AUTOSAR XML (schema 4-2-2)
package /STELLANTIS/EPT/ASWCs
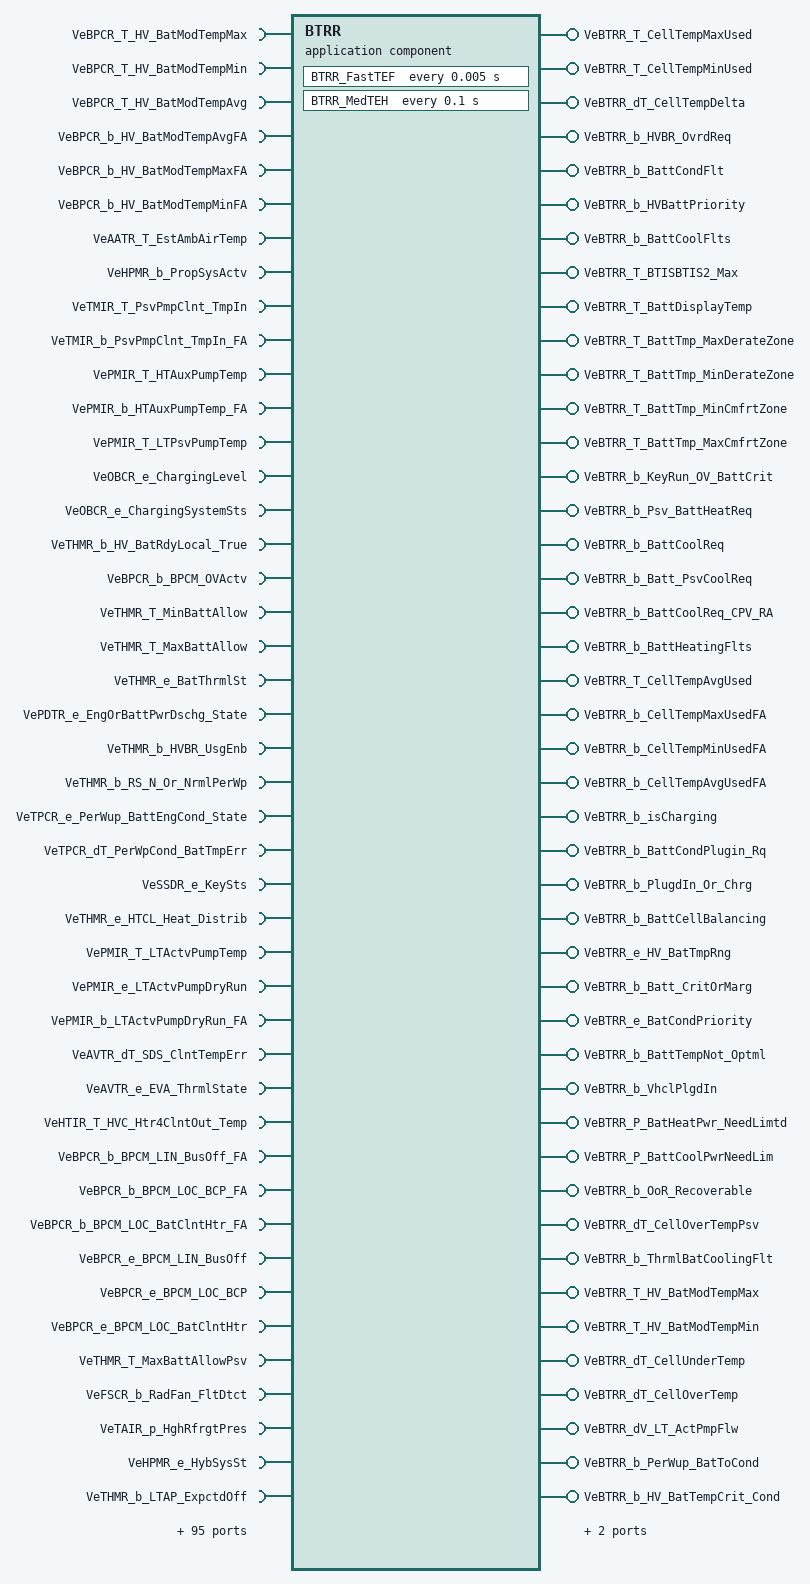
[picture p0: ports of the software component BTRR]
  application sw component type BTRR
    139 x require port:
      VeBPCR_T_HV_BatModTempMax: variation-point={short-label=vpVeBPCR_T_HV_BatModTempMax, sw-syscond=1}, nonqueued-receiver-com-spec{data-element=Value, init-value=0}, required-interface=VeBPCR_T_HV_BatModTempMax
      VeBPCR_T_HV_BatModTempMin: variation-point={short-label=vpVeBPCR_T_HV_BatModTempMin, sw-syscond=1}, nonqueued-receiver-com-spec{data-element=Value, init-value=0}, required-interface=VeBPCR_T_HV_BatModTempMin
      VeBPCR_T_HV_BatModTempAvg: variation-point={short-label=vpVeBPCR_T_HV_BatModTempAvg, sw-syscond=1}, nonqueued-receiver-com-spec{data-element=Value, init-value=0}, required-interface=VeBPCR_T_HV_BatModTempAvg
      VeBPCR_b_HV_BatModTempAvgFA: variation-point={short-label=vpVeBPCR_b_HV_BatModTempAvgFA, sw-syscond=1}, nonqueued-receiver-com-spec{data-element=Value, init-value=0}, required-interface=VeBPCR_b_HV_BatModTempAvgFA
      VeBPCR_b_HV_BatModTempMaxFA: variation-point={short-label=vpVeBPCR_b_HV_BatModTempMaxFA, sw-syscond=1}, nonqueued-receiver-com-spec{data-element=Value, init-value=0}, required-interface=VeBPCR_b_HV_BatModTempMaxFA
      VeBPCR_b_HV_BatModTempMinFA: variation-point={short-label=vpVeBPCR_b_HV_BatModTempMinFA, sw-syscond=1}, nonqueued-receiver-com-spec{data-element=Value, init-value=0}, required-interface=VeBPCR_b_HV_BatModTempMinFA
      VeAATR_T_EstAmbAirTemp: variation-point={short-label=vpVeAATR_T_EstAmbAirTemp, sw-syscond=1}, nonqueued-receiver-com-spec{data-element=Value, init-value=0}, required-interface=VeAATR_T_EstAmbAirTemp
      VeHPMR_b_PropSysActv: variation-point={short-label=vpVeHPMR_b_PropSysActv, sw-syscond=1}, nonqueued-receiver-com-spec{data-element=Value, init-value=0}, required-interface=VeHPMR_b_PropSysActv
      VeTMIR_T_PsvPmpClnt_TmpIn: variation-point={short-label=vpVeTMIR_T_PsvPmpClnt_TmpIn, sw-syscond=1}, nonqueued-receiver-com-spec{data-element=Value, init-value=0}, required-interface=VeTMIR_T_PsvPmpClnt_TmpIn
      VeTMIR_b_PsvPmpClnt_TmpIn_FA: variation-point={short-label=vpVeTMIR_b_PsvPmpClnt_TmpIn_FA, sw-syscond=1}, nonqueued-receiver-com-spec{data-element=Value, init-value=0}, required-interface=VeTMIR_b_PsvPmpClnt_TmpIn_FA
      VePMIR_T_HTAuxPumpTemp: variation-point={short-label=vpVePMIR_T_HTAuxPumpTemp, sw-syscond=1}, nonqueued-receiver-com-spec{data-element=Value, init-value=0}, required-interface=VePMIR_T_HTAuxPumpTemp
      VePMIR_b_HTAuxPumpTemp_FA: variation-point={short-label=vpVePMIR_b_HTAuxPumpTemp_FA, sw-syscond=1}, nonqueued-receiver-com-spec{data-element=Value, init-value=0}, required-interface=VePMIR_b_HTAuxPumpTemp_FA
      VePMIR_T_LTPsvPumpTemp: variation-point={short-label=vpVePMIR_T_LTPsvPumpTemp, sw-syscond=1}, nonqueued-receiver-com-spec{data-element=Value, init-value=0}, required-interface=VePMIR_T_LTPsvPumpTemp
      VeOBCR_e_ChargingLevel: variation-point={short-label=vpVeOBCR_e_ChargingLevel, sw-syscond=1}, nonqueued-receiver-com-spec{data-element=Value, init-value=CeOBCR_e_ChargingLvlDefault}, required-interface=VeOBCR_e_ChargingLevel
      VeOBCR_e_ChargingSystemSts: variation-point={short-label=vpVeOBCR_e_ChargingSystemSts, sw-syscond=1}, nonqueued-receiver-com-spec{data-element=Value, init-value=CeOBCR_e_NotCharging}, required-interface=VeOBCR_e_ChargingSystemSts
      VeTHMR_b_HV_BatRdyLocal_True: variation-point={short-label=vpVeTHMR_b_HV_BatRdyLocal_True, sw-syscond=1}, nonqueued-receiver-com-spec{data-element=Value, init-value=0}, required-interface=VeTHMR_b_HV_BatRdyLocal_True
      VeBPCR_b_BPCM_OVActv: variation-point={short-label=vpVeBPCR_b_BPCM_OVActv, sw-syscond=1}, nonqueued-receiver-com-spec{data-element=Value, init-value=0}, required-interface=VeBPCR_b_BPCM_OVActv
      VeTHMR_T_MinBattAllow: variation-point={short-label=vpVeTHMR_T_MinBattAllow, sw-syscond=1}, nonqueued-receiver-com-spec{data-element=Value, init-value=0}, required-interface=VeTHMR_T_MinBattAllow
      VeTHMR_T_MaxBattAllow: variation-point={short-label=vpVeTHMR_T_MaxBattAllow, sw-syscond=1}, nonqueued-receiver-com-spec{data-element=Value, init-value=0}, required-interface=VeTHMR_T_MaxBattAllow
      VeTHMR_e_BatThrmlSt: variation-point={short-label=vpVeTHMR_e_BatThrmlSt, sw-syscond=1}, nonqueued-receiver-com-spec{data-element=Value, init-value=CeTHMR_e_NoConditioning}, required-interface=VeTHMR_e_BatThrmlSt
      VePDTR_e_EngOrBattPwrDschg_State: variation-point={short-label=vpVePDTR_e_EngOrBattPwrDschg_State, sw-syscond=1}, nonqueued-receiver-com-spec{data-element=Value, init-value=CePDTR_e_No_Dischrg}, required-interface=VePDTR_e_EngOrBattPwrDschg_State
      VeTHMR_b_HVBR_UsgEnb: variation-point={short-label=vpVeTHMR_b_HVBR_UsgEnb, sw-syscond=1}, nonqueued-receiver-com-spec{data-element=Value, init-value=0}, required-interface=VeTHMR_b_HVBR_UsgEnb
      VeTHMR_b_RS_N_Or_NrmlPerWp: variation-point={short-label=vpVeTHMR_b_RS_N_Or_NrmlPerWp, sw-syscond=1}, nonqueued-receiver-com-spec{data-element=Value, init-value=0}, required-interface=VeTHMR_b_RS_N_Or_NrmlPerWp
      VeTPCR_e_PerWup_BattEngCond_State: variation-point={short-label=vpVeTPCR_e_PerWup_BattEngCond_State, sw-syscond=1}, nonqueued-receiver-com-spec{data-element=Value, init-value=CeTPCR_e_NoneOfEngBatt_Cond}, required-interface=VeTPCR_e_PerWup_BattEngCond_State
      VeTPCR_dT_PerWpCond_BatTmpErr: variation-point={short-label=vpVeTPCR_dT_PerWpCond_BatTmpErr, sw-syscond=1}, nonqueued-receiver-com-spec{data-element=Value, init-value=0}, required-interface=VeTPCR_dT_PerWpCond_BatTmpErr
      VeSSDR_e_KeySts: variation-point={short-label=vpVeSSDR_e_KeySts, sw-syscond=1}, nonqueued-receiver-com-spec{data-element=Value, init-value=CeSSDR_e_KeyOff}, required-interface=VeSSDR_e_KeySts
      VeTHMR_e_HTCL_Heat_Distrib: variation-point={short-label=vpVeTHMR_e_HTCL_Heat_Distrib, sw-syscond=1}, nonqueued-receiver-com-spec{data-element=Value, init-value=CeTHMR_e_NoHeating}, required-interface=VeTHMR_e_HTCL_Heat_Distrib
      VePMIR_T_LTActvPumpTemp: variation-point={short-label=vpVePMIR_T_LTActvPumpTemp, sw-syscond=1}, nonqueued-receiver-com-spec{data-element=Value, init-value=0}, required-interface=VePMIR_T_LTActvPumpTemp
      VePMIR_e_LTActvPumpDryRun: variation-point={short-label=vpVePMIR_e_LTActvPumpDryRun, sw-syscond=1}, nonqueued-receiver-com-spec{data-element=Value, init-value=CePMPR_e_FTSNA_False}, required-interface=VePMIR_e_LTActvPumpDryRun
      VePMIR_b_LTActvPumpDryRun_FA: variation-point={short-label=vpVePMIR_b_LTActvPumpDryRun_FA, sw-syscond=1}, nonqueued-receiver-com-spec{data-element=Value, init-value=0}, required-interface=VePMIR_b_LTActvPumpDryRun_FA
      VeAVTR_dT_SDS_ClntTempErr: variation-point={short-label=vpVeAVTR_dT_SDS_ClntTempErr, sw-syscond=1}, nonqueued-receiver-com-spec{data-element=Value, init-value=0}, required-interface=VeAVTR_dT_SDS_ClntTempErr
      VeAVTR_e_EVA_ThrmlState: variation-point={short-label=vpVeAVTR_e_EVA_ThrmlState, sw-syscond=1}, nonqueued-receiver-com-spec{data-element=Value, init-value=CeAVTR_e_NoEVACond}, required-interface=VeAVTR_e_EVA_ThrmlState
      VeHTIR_T_HVC_Htr4ClntOut_Temp: variation-point={short-label=vpVeHTIR_T_HVC_Htr4ClntOut_Temp, sw-syscond=1}, nonqueued-receiver-com-spec{data-element=Value, init-value=0}, required-interface=VeHTIR_T_HVC_Htr4ClntOut_Temp
      VeBPCR_b_BPCM_LIN_BusOff_FA: variation-point={short-label=vpVeBPCR_b_BPCM_LIN_BusOff_FA, sw-syscond=1}, nonqueued-receiver-com-spec{data-element=Value, init-value=0}, required-interface=VeBPCR_b_BPCM_LIN_BusOff_FA
      VeBPCR_b_BPCM_LOC_BCP_FA: variation-point={short-label=vpVeBPCR_b_BPCM_LOC_BCP_FA, sw-syscond=1}, nonqueued-receiver-com-spec{data-element=Value, init-value=0}, required-interface=VeBPCR_b_BPCM_LOC_BCP_FA
      VeBPCR_b_BPCM_LOC_BatClntHtr_FA: variation-point={short-label=vpVeBPCR_b_BPCM_LOC_BatClntHtr_FA, sw-syscond=1}, nonqueued-receiver-com-spec{data-element=Value, init-value=0}, required-interface=VeBPCR_b_BPCM_LOC_BatClntHtr_FA
      VeBPCR_e_BPCM_LIN_BusOff: variation-point={short-label=vpVeBPCR_e_BPCM_LIN_BusOff, sw-syscond=1}, nonqueued-receiver-com-spec{data-element=Value, init-value=CeBPCR_e_LIN_BusOff_Disabled}, required-interface=VeBPCR_e_BPCM_LIN_BusOff
      VeBPCR_e_BPCM_LOC_BCP: variation-point={short-label=vpVeBPCR_e_BPCM_LOC_BCP, sw-syscond=1}, nonqueued-receiver-com-spec{data-element=Value, init-value=CeBPCR_e_LOC_BCP_False}, required-interface=VeBPCR_e_BPCM_LOC_BCP
      VeBPCR_e_BPCM_LOC_BatClntHtr: variation-point={short-label=vpVeBPCR_e_BPCM_LOC_BatClntHtr, sw-syscond=1}, nonqueued-receiver-com-spec{data-element=Value, init-value=CeBPCR_e_LOC_BatClntHtr_False}, required-interface=VeBPCR_e_BPCM_LOC_BatClntHtr
      VeTHMR_T_MaxBattAllowPsv: variation-point={short-label=vpVeTHMR_T_MaxBattAllowPsv, sw-syscond=1}, nonqueued-receiver-com-spec{data-element=Value, init-value=0}, required-interface=VeTHMR_T_MaxBattAllowPsv
      VeFSCR_b_RadFan_FltDtct: variation-point={short-label=vpVeFSCR_b_RadFan_FltDtct, sw-syscond=1}, nonqueued-receiver-com-spec{data-element=Value, init-value=0}, required-interface=VeFSCR_b_RadFan_FltDtct
      VeTAIR_p_HghRfrgtPres: variation-point={short-label=vpVeTAIR_p_HghRfrgtPres, sw-syscond=1}, nonqueued-receiver-com-spec{data-element=Value, init-value=0}, required-interface=VeTAIR_p_HghRfrgtPres
      VeHPMR_e_HybSysSt: variation-point={short-label=vpVeHPMR_e_HybSysSt, sw-syscond=1}, nonqueued-receiver-com-spec{data-element=Value, init-value=CeHPMR_e_POWERUP}, required-interface=VeHPMR_e_HybSysSt
      VeTHMR_b_LTAP_ExpctdOff: variation-point={short-label=vpVeTHMR_b_LTAP_ExpctdOff, sw-syscond=1}, nonqueued-receiver-com-spec{data-element=Value, init-value=0}, required-interface=VeTHMR_b_LTAP_ExpctdOff
      VeAVTR_e_SDS_Actual_State: variation-point={short-label=vpVeAVTR_e_SDS_Actual_State, sw-syscond=1}, nonqueued-receiver-com-spec{data-element=Value, init-value=CeTRIR_e_SDS_OFF}, required-interface=VeAVTR_e_SDS_Actual_State
      VeAVTR_T_SDS_Clnt_TmpIn_Act: variation-point={short-label=vpVeAVTR_T_SDS_Clnt_TmpIn_Act, sw-syscond=1}, nonqueued-receiver-com-spec{data-element=Value, init-value=0}, required-interface=VeAVTR_T_SDS_Clnt_TmpIn_Act
      VeBPCR_e_HV_BatCntctrStat: variation-point={short-label=vpVeBPCR_e_HV_BatCntctrStat, sw-syscond=1}, nonqueued-receiver-com-spec{data-element=Value, init-value=CeHVTR_e_Open}, required-interface=VeBPCR_e_HV_BatCntctrStat
      VeIDCR_T_APMTemp1: variation-point={short-label=vpVeIDCR_T_APMTemp1, sw-syscond=1}, nonqueued-receiver-com-spec{data-element=Value, init-value=0}, required-interface=VeIDCR_T_APMTemp1
      VeIDCR_T_APMTemp2: variation-point={short-label=vpVeIDCR_T_APMTemp2, sw-syscond=1}, nonqueued-receiver-com-spec{data-element=Value, init-value=0}, required-interface=VeIDCR_T_APMTemp2
      VePMIR_e_HTAuxPumpDryRun: variation-point={short-label=vpVePMIR_e_HTAuxPumpDryRun, sw-syscond=1}, nonqueued-receiver-com-spec{data-element=Value, init-value=CePMPR_e_FTSNA_False}, required-interface=VePMIR_e_HTAuxPumpDryRun
      VePMIR_b_HTAuxPumpDryRun_FA: variation-point={short-label=vpVePMIR_b_HTAuxPumpDryRun_FA, sw-syscond=1}, nonqueued-receiver-com-spec{data-element=Value, init-value=0}, required-interface=VePMIR_b_HTAuxPumpDryRun_FA
      VeHTIR_e_HV_ElecClntHtr4_Sts: variation-point={short-label=vpVeHTIR_e_HV_ElecClntHtr4_Sts, sw-syscond=1}, nonqueued-receiver-com-spec{data-element=Value, init-value=CeHTIR_e_HtrSts_Off}, required-interface=VeHTIR_e_HV_ElecClntHtr4_Sts
      VeTRIR_T_HV_BatClntTmp_In: variation-point={short-label=vpVeTRIR_T_HV_BatClntTmp_In, sw-syscond=1}, nonqueued-receiver-com-spec{data-element=Value, init-value=0}, required-interface=VeTRIR_T_HV_BatClntTmp_In
      VeTRIR_T_HV_BatClntTmpOut: variation-point={short-label=vpVeTRIR_T_HV_BatClntTmpOut, sw-syscond=1}, nonqueued-receiver-com-spec{data-element=Value, init-value=0}, required-interface=VeTRIR_T_HV_BatClntTmpOut
      VeTRIR_T_HV_BatClntTmp2_In: variation-point={short-label=vpVeTRIR_T_HV_BatClntTmp2_In, sw-syscond=1}, nonqueued-receiver-com-spec{data-element=Value, init-value=0}, required-interface=VeTRIR_T_HV_BatClntTmp2_In
      VeTRIR_T_HV_BatClntTmpOut2: variation-point={short-label=vpVeTRIR_T_HV_BatClntTmpOut2, sw-syscond=1}, nonqueued-receiver-com-spec{data-element=Value, init-value=0}, required-interface=VeTRIR_T_HV_BatClntTmpOut2
      VeHTIR_e_HV_ElecClntHtr3_Sts: variation-point={short-label=vpVeHTIR_e_HV_ElecClntHtr3_Sts, sw-syscond=1}, nonqueued-receiver-com-spec{data-element=Value, init-value=CeHTIR_e_HtrSts_Off}, required-interface=VeHTIR_e_HV_ElecClntHtr3_Sts
      VeBRDR_b_LTAP_Rqt_LoLv_Diag: variation-point={short-label=vpVeBRDR_b_LTAP_Rqt_LoLv_Diag, sw-syscond=1}, nonqueued-receiver-com-spec{data-element=Value, init-value=0}, required-interface=VeBRDR_b_LTAP_Rqt_LoLv_Diag
      VePMTR_b_ThrmlSystRly_EnblCmnd: variation-point={short-label=vpVePMTR_b_ThrmlSystRly_EnblCmnd, sw-syscond=1}, nonqueued-receiver-com-spec{data-element=Value, init-value=0}, required-interface=VePMTR_b_ThrmlSystRly_EnblCmnd
      VeBRDR_b_HV_BTIS_FltDtct: variation-point={short-label=vpVeBRDR_b_HV_BTIS_FltDtct, sw-syscond=1}, nonqueued-receiver-com-spec{data-element=Value, init-value=0}, required-interface=VeBRDR_b_HV_BTIS_FltDtct
      VeBRDR_b_HV_BTIS2_FltDtct: variation-point={short-label=vpVeBRDR_b_HV_BTIS2_FltDtct, sw-syscond=1}, nonqueued-receiver-com-spec{data-element=Value, init-value=0}, required-interface=VeBRDR_b_HV_BTIS2_FltDtct
      VeBRDR_b_HV_BTOS2_FltDtct: variation-point={short-label=vpVeBRDR_b_HV_BTOS2_FltDtct, sw-syscond=1}, nonqueued-receiver-com-spec{data-element=Value, init-value=0}, required-interface=VeBRDR_b_HV_BTOS2_FltDtct
      VeVLDR_b_EXV_PressElctrFlt_FltDtct: variation-point={short-label=vpVeVLDR_b_EXV_PressElctrFlt_FltDtct, sw-syscond=1}, nonqueued-receiver-com-spec{data-element=Value, init-value=0}, required-interface=VeVLDR_b_EXV_PressElctrFlt_FltDtct
      VeVLDR_b_EXV_TempElctrFlt_FltDtct: variation-point={short-label=vpVeVLDR_b_EXV_TempElctrFlt_FltDtct, sw-syscond=1}, nonqueued-receiver-com-spec{data-element=Value, init-value=0}, required-interface=VeVLDR_b_EXV_TempElctrFlt_FltDtct
      VeTHMR_T_MinBattAllowPsv: variation-point={short-label=vpVeTHMR_T_MinBattAllowPsv, sw-syscond=1}, nonqueued-receiver-com-spec{data-element=Value, init-value=0}, required-interface=VeTHMR_T_MinBattAllowPsv
      VeHSWR_b_HoodOpen: variation-point={short-label=vpVeHSWR_b_HoodOpen, sw-syscond=1}, nonqueued-receiver-com-spec{data-element=Value, init-value=0}, required-interface=VeHSWR_b_HoodOpen
      VePWDR_e_HVOverVoltFailure: variation-point={short-label=vpVePWDR_e_HVOverVoltFailure, sw-syscond=1}, nonqueued-receiver-com-spec{data-element=Value, init-value=CeHVTR_e_HVOverVoltPass}, required-interface=VePWDR_e_HVOverVoltFailure
      VeVLDR_b_EXV_PerfDiag_FltDtct: variation-point={short-label=vpVeVLDR_b_EXV_PerfDiag_FltDtct, sw-syscond=1}, nonqueued-receiver-com-spec{data-element=Value, init-value=0}, required-interface=VeVLDR_b_EXV_PerfDiag_FltDtct
      VeVLDR_b_EXV_PressSens_FltDtct: variation-point={short-label=vpVeVLDR_b_EXV_PressSens_FltDtct, sw-syscond=1}, nonqueued-receiver-com-spec{data-element=Value, init-value=0}, required-interface=VeVLDR_b_EXV_PressSens_FltDtct
      VeVLDR_b_EXV_TempSens_FltDtct: variation-point={short-label=vpVeVLDR_b_EXV_TempSens_FltDtct, sw-syscond=1}, nonqueued-receiver-com-spec{data-element=Value, init-value=0}, required-interface=VeVLDR_b_EXV_TempSens_FltDtct
      VeTHMR_T_AHPInletTempArb: variation-point={short-label=vpVeTHMR_T_AHPInletTempArb, sw-syscond=1}, nonqueued-receiver-com-spec{data-element=Value, init-value=0}, required-interface=VeTHMR_T_AHPInletTempArb
      VeRCVR_e_CPV_Valve_Stuck_State: variation-point={short-label=vpVeRCVR_e_CPV_Valve_Stuck_State, sw-syscond=1}, nonqueued-receiver-com-spec{data-element=Value, init-value=CeRCVR_e_Closed}, required-interface=VeRCVR_e_CPV_Valve_Stuck_State
      VeRCVR_e_LTR_Valve_Stuck_State: variation-point={short-label=vpVeRCVR_e_LTR_Valve_Stuck_State, sw-syscond=1}, nonqueued-receiver-com-spec{data-element=Value, init-value=CeRCVR_e_Closed}, required-interface=VeRCVR_e_LTR_Valve_Stuck_State
      VeDMAB_y_StatusByte_MtrElect_CoolPmpATempSnsrPerf: variation-point={short-label=vpVeDMAB_y_StatusByte_MtrElect_CoolPmpATempSnsrPerf, sw-syscond=1}, nonqueued-receiver-com-spec{data-element=Value, init-value=0}, required-interface=VeDMAB_y_StatusByte_MtrElect_CoolPmpATempSnsrPerf
      VeDMAB_y_StatusByte_BattCoolPmpHtrBTempSnsrPerf: variation-point={short-label=vpVeDMAB_y_StatusByte_BattCoolPmpHtrBTempSnsrPerf, sw-syscond=1}, nonqueued-receiver-com-spec{data-element=Value, init-value=0}, required-interface=VeDMAB_y_StatusByte_BattCoolPmpHtrBTempSnsrPerf
      VeDMAB_y_StatusByte_BattHeat: variation-point={short-label=vpVeDMAB_y_StatusByte_BattHeat, sw-syscond=1}, nonqueued-receiver-com-spec{data-element=Value, init-value=0}, required-interface=VeDMAB_y_StatusByte_BattHeat
      VeDMAB_y_StatusByte_CoolantHeaterBPerf: variation-point={short-label=vpVeDMAB_y_StatusByte_CoolantHeaterBPerf, sw-syscond=1}, nonqueued-receiver-com-spec{data-element=Value, init-value=0}, required-interface=VeDMAB_y_StatusByte_CoolantHeaterBPerf
      VeDMAB_y_StatusByte_HeatingElmntPerf: variation-point={short-label=vpVeDMAB_y_StatusByte_HeatingElmntPerf, sw-syscond=1}, nonqueued-receiver-com-spec{data-element=Value, init-value=0}, required-interface=VeDMAB_y_StatusByte_HeatingElmntPerf
      VeDMAB_y_StatusByte_CoolOutTempSnsCkt: variation-point={short-label=vpVeDMAB_y_StatusByte_CoolOutTempSnsCkt, sw-syscond=1}, nonqueued-receiver-com-spec{data-element=Value, init-value=0}, required-interface=VeDMAB_y_StatusByte_CoolOutTempSnsCkt
      VeDMAB_y_StatusByte_HB_CT_SnsrPerf: variation-point={short-label=vpVeDMAB_y_StatusByte_HB_CT_SnsrPerf, sw-syscond=1}, nonqueued-receiver-com-spec{data-element=Value, init-value=0}, required-interface=VeDMAB_y_StatusByte_HB_CT_SnsrPerf
      VeDMAB_y_StatusByte_BattCoolLvlLow: variation-point={short-label=vpVeDMAB_y_StatusByte_BattCoolLvlLow, sw-syscond=1}, nonqueued-receiver-com-spec{data-element=Value, init-value=0}, required-interface=VeDMAB_y_StatusByte_BattCoolLvlLow
      VeDMAB_y_StatusByte_BattCoolLvlSnsCkt: variation-point={short-label=vpVeDMAB_y_StatusByte_BattCoolLvlSnsCkt, sw-syscond=1}, nonqueued-receiver-com-spec{data-element=Value, init-value=0}, required-interface=VeDMAB_y_StatusByte_BattCoolLvlSnsCkt
      VeDMAB_y_StatusByte_BattCool: variation-point={short-label=vpVeDMAB_y_StatusByte_BattCool, sw-syscond=1}, nonqueued-receiver-com-spec{data-element=Value, init-value=0}, required-interface=VeDMAB_y_StatusByte_BattCool
      VeDMAB_y_StatusByte_CoolCtrlVlv1CktHi: variation-point={short-label=vpVeDMAB_y_StatusByte_CoolCtrlVlv1CktHi, sw-syscond=1}, nonqueued-receiver-com-spec{data-element=Value, init-value=0}, required-interface=VeDMAB_y_StatusByte_CoolCtrlVlv1CktHi
      VeDMAB_y_StatusByte_CoolCtrlVlv1CktLo: variation-point={short-label=vpVeDMAB_y_StatusByte_CoolCtrlVlv1CktLo, sw-syscond=1}, nonqueued-receiver-com-spec{data-element=Value, init-value=0}, required-interface=VeDMAB_y_StatusByte_CoolCtrlVlv1CktLo
      VeDMAB_y_StatusByte_CoolCtrlVlv1Ckt: variation-point={short-label=vpVeDMAB_y_StatusByte_CoolCtrlVlv1Ckt, sw-syscond=1}, nonqueued-receiver-com-spec{data-element=Value, init-value=0}, required-interface=VeDMAB_y_StatusByte_CoolCtrlVlv1Ckt
      VeDMAB_y_StatusByte_EACPerf: variation-point={short-label=vpVeDMAB_y_StatusByte_EACPerf, sw-syscond=1}, nonqueued-receiver-com-spec{data-element=Value, init-value=0}, required-interface=VeDMAB_y_StatusByte_EACPerf
      VeDMAB_y_StatusByte_LostCommEAC: variation-point={short-label=vpVeDMAB_y_StatusByte_LostCommEAC, sw-syscond=1}, nonqueued-receiver-com-spec{data-element=Value, init-value=0}, required-interface=VeDMAB_y_StatusByte_LostCommEAC
      VeDMAB_y_StatusByte_CT2_SnsrCktHi: variation-point={short-label=vpVeDMAB_y_StatusByte_CT2_SnsrCktHi, sw-syscond=1}, nonqueued-receiver-com-spec{data-element=Value, init-value=0}, required-interface=VeDMAB_y_StatusByte_CT2_SnsrCktHi
      VeDMAB_y_StatusByte_CT2_SnsrCktLo: variation-point={short-label=vpVeDMAB_y_StatusByte_CT2_SnsrCktLo, sw-syscond=1}, nonqueued-receiver-com-spec{data-element=Value, init-value=0}, required-interface=VeDMAB_y_StatusByte_CT2_SnsrCktLo
      VeDMAB_y_StatusByte_CT2_SnsrPerf: variation-point={short-label=vpVeDMAB_y_StatusByte_CT2_SnsrPerf, sw-syscond=1}, nonqueued-receiver-com-spec{data-element=Value, init-value=0}, required-interface=VeDMAB_y_StatusByte_CT2_SnsrPerf
      VeDMAB_y_StatusByte_CoolHeaterAPerf: variation-point={short-label=vpVeDMAB_y_StatusByte_CoolHeaterAPerf, sw-syscond=1}, nonqueued-receiver-com-spec{data-element=Value, init-value=0}, required-interface=VeDMAB_y_StatusByte_CoolHeaterAPerf
      VeDMAB_y_StatusByte_CoolPmpATempSnsrPerf: variation-point={short-label=vpVeDMAB_y_StatusByte_CoolPmpATempSnsrPerf, sw-syscond=1}, nonqueued-receiver-com-spec{data-element=Value, init-value=0}, required-interface=VeDMAB_y_StatusByte_CoolPmpATempSnsrPerf
      VeDMAB_y_StatusByte_CoolantVlvB_CktHi: variation-point={short-label=vpVeDMAB_y_StatusByte_CoolantVlvB_CktHi, sw-syscond=1}, nonqueued-receiver-com-spec{data-element=Value, init-value=0}, required-interface=VeDMAB_y_StatusByte_CoolantVlvB_CktHi
      VeDMAB_y_StatusByte_CoolantVlvB_CktLo: variation-point={short-label=vpVeDMAB_y_StatusByte_CoolantVlvB_CktLo, sw-syscond=1}, nonqueued-receiver-com-spec{data-element=Value, init-value=0}, required-interface=VeDMAB_y_StatusByte_CoolantVlvB_CktLo
      VeDMAB_y_StatusByte_CoolantVlvB_Ckt: variation-point={short-label=vpVeDMAB_y_StatusByte_CoolantVlvB_Ckt, sw-syscond=1}, nonqueued-receiver-com-spec{data-element=Value, init-value=0}, required-interface=VeDMAB_y_StatusByte_CoolantVlvB_Ckt
      VeDMAB_y_StatusByte_CoolantVlvB_StkClsd: variation-point={short-label=vpVeDMAB_y_StatusByte_CoolantVlvB_StkClsd, sw-syscond=1}, nonqueued-receiver-com-spec{data-element=Value, init-value=0}, required-interface=VeDMAB_y_StatusByte_CoolantVlvB_StkClsd
      VeDMAB_y_StatusByte_ECH_TempIn: variation-point={short-label=vpVeDMAB_y_StatusByte_ECH_TempIn, sw-syscond=1}, nonqueued-receiver-com-spec{data-element=Value, init-value=0}, required-interface=VeDMAB_y_StatusByte_ECH_TempIn
      VeDMAB_y_StatusByte_ECH_TempOut: variation-point={short-label=vpVeDMAB_y_StatusByte_ECH_TempOut, sw-syscond=1}, nonqueued-receiver-com-spec{data-element=Value, init-value=0}, required-interface=VeDMAB_y_StatusByte_ECH_TempOut
      VeDMAB_y_StatusByte_LostCommCoolHtrA: variation-point={short-label=vpVeDMAB_y_StatusByte_LostCommCoolHtrA, sw-syscond=1}, nonqueued-receiver-com-spec{data-element=Value, init-value=0}, required-interface=VeDMAB_y_StatusByte_LostCommCoolHtrA
      VeDMAB_y_StatusByte_LostCommHighVolCabinAirHtr: variation-point={short-label=vpVeDMAB_y_StatusByte_LostCommHighVolCabinAirHtr, sw-syscond=1}, nonqueued-receiver-com-spec{data-element=Value, init-value=0}, required-interface=VeDMAB_y_StatusByte_LostCommHighVolCabinAirHtr
      VeDMAB_y_StatusByte_LostCommACRefrigExpVlvActA: variation-point={short-label=vpVeDMAB_y_StatusByte_LostCommACRefrigExpVlvActA, sw-syscond=1}, nonqueued-receiver-com-spec{data-element=Value, init-value=0}, required-interface=VeDMAB_y_StatusByte_LostCommACRefrigExpVlvActA
      VeDMAB_y_StatusByte_CoolPmpACtrlCktPerf: variation-point={short-label=vpVeDMAB_y_StatusByte_CoolPmpACtrlCktPerf, sw-syscond=1}, nonqueued-receiver-com-spec{data-element=Value, init-value=0}, required-interface=VeDMAB_y_StatusByte_CoolPmpACtrlCktPerf
      VeDMAB_y_StatusByte_LIN1_BusOff: variation-point={short-label=vpVeDMAB_y_StatusByte_LIN1_BusOff, sw-syscond=1}, nonqueued-receiver-com-spec{data-element=Value, init-value=0}, required-interface=VeDMAB_y_StatusByte_LIN1_BusOff
      VeDMAB_y_StatusByte_LIN2_BusOff: variation-point={short-label=vpVeDMAB_y_StatusByte_LIN2_BusOff, sw-syscond=1}, nonqueued-receiver-com-spec{data-element=Value, init-value=0}, required-interface=VeDMAB_y_StatusByte_LIN2_BusOff
      VeDMAB_y_StatusByte_LostCommCoolPmpA: variation-point={short-label=vpVeDMAB_y_StatusByte_LostCommCoolPmpA, sw-syscond=1}, nonqueued-receiver-com-spec{data-element=Value, init-value=0}, required-interface=VeDMAB_y_StatusByte_LostCommCoolPmpA
      VeDMAB_y_StatusByte_CoolantVlvA_CktHi: variation-point={short-label=vpVeDMAB_y_StatusByte_CoolantVlvA_CktHi, sw-syscond=1}, nonqueued-receiver-com-spec{data-element=Value, init-value=0}, required-interface=VeDMAB_y_StatusByte_CoolantVlvA_CktHi
      VeDMAB_y_StatusByte_CoolantVlvA_CktLo: variation-point={short-label=vpVeDMAB_y_StatusByte_CoolantVlvA_CktLo, sw-syscond=1}, nonqueued-receiver-com-spec{data-element=Value, init-value=0}, required-interface=VeDMAB_y_StatusByte_CoolantVlvA_CktLo
      VeDMAB_y_StatusByte_CoolantVlvA_Ckt: variation-point={short-label=vpVeDMAB_y_StatusByte_CoolantVlvA_Ckt, sw-syscond=1}, nonqueued-receiver-com-spec{data-element=Value, init-value=0}, required-interface=VeDMAB_y_StatusByte_CoolantVlvA_Ckt
      VeDMAB_y_StatusByte_CoolantVlvA_Perf: variation-point={short-label=vpVeDMAB_y_StatusByte_CoolantVlvA_Perf, sw-syscond=1}, nonqueued-receiver-com-spec{data-element=Value, init-value=0}, required-interface=VeDMAB_y_StatusByte_CoolantVlvA_Perf
      VeDMAB_y_StatusByte_CommBusOff: variation-point={short-label=vpVeDMAB_y_StatusByte_CommBusOff, sw-syscond=1}, nonqueued-receiver-com-spec{data-element=Value, init-value=0}, required-interface=VeDMAB_y_StatusByte_CommBusOff
      VeDMAB_y_StatusByte_CommBus_B_Off: variation-point={short-label=vpVeDMAB_y_StatusByte_CommBus_B_Off, sw-syscond=1}, nonqueued-receiver-com-spec{data-element=Value, init-value=0}, required-interface=VeDMAB_y_StatusByte_CommBus_B_Off
      VeDMAB_y_StatusByte_LosCommBECM_A_CANC11: variation-point={short-label=vpVeDMAB_y_StatusByte_LosCommBECM_A_CANC11, sw-syscond=1}, nonqueued-receiver-com-spec{data-element=Value, init-value=0}, required-interface=VeDMAB_y_StatusByte_LosCommBECM_A_CANC11
      VeDMAB_y_StatusByte_LosCommBECM_A: variation-point={short-label=vpVeDMAB_y_StatusByte_LosCommBECM_A, sw-syscond=1}, nonqueued-receiver-com-spec{data-element=Value, init-value=0}, required-interface=VeDMAB_y_StatusByte_LosCommBECM_A
      VeDMAB_y_StatusByte_BattCoolPmpATempSnsrPerf: variation-point={short-label=vpVeDMAB_y_StatusByte_BattCoolPmpATempSnsrPerf, sw-syscond=1}, nonqueued-receiver-com-spec{data-element=Value, init-value=0}, required-interface=VeDMAB_y_StatusByte_BattCoolPmpATempSnsrPerf
      VeDMAB_y_StatusByte_BattCoolPmpPerf: variation-point={short-label=vpVeDMAB_y_StatusByte_BattCoolPmpPerf, sw-syscond=1}, nonqueued-receiver-com-spec{data-element=Value, init-value=0}, required-interface=VeDMAB_y_StatusByte_BattCoolPmpPerf
      VeDMAB_y_StatusByte_AC_RefrigPresSnsrAHi: variation-point={short-label=vpVeDMAB_y_StatusByte_AC_RefrigPresSnsrAHi, sw-syscond=1}, nonqueued-receiver-com-spec{data-element=Value, init-value=0}, required-interface=VeDMAB_y_StatusByte_AC_RefrigPresSnsrAHi
      VeDMAB_y_StatusByte_AC_RefrigPresSnsrALo: variation-point={short-label=vpVeDMAB_y_StatusByte_AC_RefrigPresSnsrALo, sw-syscond=1}, nonqueued-receiver-com-spec{data-element=Value, init-value=0}, required-interface=VeDMAB_y_StatusByte_AC_RefrigPresSnsrALo
      VeDMAB_y_StatusByte_AC_RefrigPresSnsrAPerf: variation-point={short-label=vpVeDMAB_y_StatusByte_AC_RefrigPresSnsrAPerf, sw-syscond=1}, nonqueued-receiver-com-spec{data-element=Value, init-value=0}, required-interface=VeDMAB_y_StatusByte_AC_RefrigPresSnsrAPerf
      VeDMAB_y_StatusByte_ThrmlRlyCtrlCkt: variation-point={short-label=vpVeDMAB_y_StatusByte_ThrmlRlyCtrlCkt, sw-syscond=1}, nonqueued-receiver-com-spec{data-element=Value, init-value=0}, required-interface=VeDMAB_y_StatusByte_ThrmlRlyCtrlCkt
      VeTHMR_e_VehThermSt: variation-point={short-label=vpVeTHMR_e_VehThermSt, sw-syscond=1}, nonqueued-receiver-com-spec{data-element=Value, init-value=CeTHMR_e_TempAllowNormalDrive}, required-interface=VeTHMR_e_VehThermSt
      VeTHMR_T_LTCLTgt_BattActvPsvHeating: variation-point={short-label=vpVeTHMR_T_LTCLTgt_BattActvPsvHeating, sw-syscond=1}, nonqueued-receiver-com-spec{data-element=Value, init-value=0}, required-interface=VeTHMR_T_LTCLTgt_BattActvPsvHeating
      VeTHMR_e_CabHeatThermalState: variation-point={short-label=vpVeTHMR_e_CabHeatThermalState, sw-syscond=1}, nonqueued-receiver-com-spec{data-element=Value, init-value=CeTHMR_e_NoCabinHeating}, required-interface=VeTHMR_e_CabHeatThermalState
      VeDMAB_y_StatusByte_LIN3_BusOff: variation-point={short-label=vpVeDMAB_y_StatusByte_LIN3_BusOff, sw-syscond=1}, nonqueued-receiver-com-spec{data-element=Value, init-value=0}, required-interface=VeDMAB_y_StatusByte_LIN3_BusOff
      VeDMAB_y_StatusByte_LostCommHB_CoolPmp: variation-point={short-label=vpVeDMAB_y_StatusByte_LostCommHB_CoolPmp, sw-syscond=1}, nonqueued-receiver-com-spec{data-element=Value, init-value=0}, required-interface=VeDMAB_y_StatusByte_LostCommHB_CoolPmp
      VeDMAB_y_StatusByte_BattCoolPmpOveSpd: variation-point={short-label=vpVeDMAB_y_StatusByte_BattCoolPmpOveSpd, sw-syscond=1}, nonqueued-receiver-com-spec{data-element=Value, init-value=0}, required-interface=VeDMAB_y_StatusByte_BattCoolPmpOveSpd
      VeDMAB_y_StatusByte_AC_RefrigTempSnsrCPerf: variation-point={short-label=vpVeDMAB_y_StatusByte_AC_RefrigTempSnsrCPerf, sw-syscond=1}, nonqueued-receiver-com-spec{data-element=Value, init-value=0}, required-interface=VeDMAB_y_StatusByte_AC_RefrigTempSnsrCPerf
      VeDMAB_y_StatusByte_LostCommACRefrigExpVlvActC: variation-point={short-label=vpVeDMAB_y_StatusByte_LostCommACRefrigExpVlvActC, sw-syscond=1}, nonqueued-receiver-com-spec{data-element=Value, init-value=0}, required-interface=VeDMAB_y_StatusByte_LostCommACRefrigExpVlvActC
      VeVLDR_b_EEXV_PressSens_FltDtct: variation-point={short-label=vpVeVLDR_b_EEXV_PressSens_FltDtct, sw-syscond=1}, nonqueued-receiver-com-spec{data-element=Value, init-value=0}, required-interface=VeVLDR_b_EEXV_PressSens_FltDtct
      VeVLDR_b_EEXV_PerfDiag_FltDtct: variation-point={short-label=vpVeVLDR_b_EEXV_PerfDiag_FltDtct, sw-syscond=1}, nonqueued-receiver-com-spec{data-element=Value, init-value=0}, required-interface=VeVLDR_b_EEXV_PerfDiag_FltDtct
      VeDMAB_y_StatusByte_LostCommACRefrigExpVlvActD: variation-point={short-label=vpVeDMAB_y_StatusByte_LostCommACRefrigExpVlvActD, sw-syscond=1}, nonqueued-receiver-com-spec{data-element=Value, init-value=0}, required-interface=VeDMAB_y_StatusByte_LostCommACRefrigExpVlvActD
      VeDMAB_y_StatusByte_AC_RefrigTempSnsr4CktPerf: variation-point={short-label=vpVeDMAB_y_StatusByte_AC_RefrigTempSnsr4CktPerf, sw-syscond=1}, nonqueued-receiver-com-spec{data-element=Value, init-value=0}, required-interface=VeDMAB_y_StatusByte_AC_RefrigTempSnsr4CktPerf
      VeDMAB_y_StatusByte_AC_RefrigTempSnsr5CktPerf: variation-point={short-label=vpVeDMAB_y_StatusByte_AC_RefrigTempSnsr5CktPerf, sw-syscond=1}, nonqueued-receiver-com-spec{data-element=Value, init-value=0}, required-interface=VeDMAB_y_StatusByte_AC_RefrigTempSnsr5CktPerf
      VeDMAB_y_StatusByte_AC_RefrigTempSnsr5CktShotoGro: variation-point={short-label=vpVeDMAB_y_StatusByte_AC_RefrigTempSnsr5CktShotoGro, sw-syscond=1}, nonqueued-receiver-com-spec{data-element=Value, init-value=0}, required-interface=VeDMAB_y_StatusByte_AC_RefrigTempSnsr5CktShotoGro
      VeDMAB_y_StatusByte_AC_RefrigTempSnsr5CktShotoBat: variation-point={short-label=vpVeDMAB_y_StatusByte_AC_RefrigTempSnsr5CktShotoBat, sw-syscond=1}, nonqueued-receiver-com-spec{data-element=Value, init-value=0}, required-interface=VeDMAB_y_StatusByte_AC_RefrigTempSnsr5CktShotoBat
      VeVLDR_b_OEXV_PerfDiag_FltDtct: variation-point={short-label=vpVeVLDR_b_OEXV_PerfDiag_FltDtct, sw-syscond=1}, nonqueued-receiver-com-spec{data-element=Value, init-value=0}, required-interface=VeVLDR_b_OEXV_PerfDiag_FltDtct
      VeVLDR_b_OEXV_PressElctrFlt_FltDtct: variation-point={short-label=vpVeVLDR_b_OEXV_PressElctrFlt_FltDtct, sw-syscond=1}, nonqueued-receiver-com-spec{data-element=Value, init-value=0}, required-interface=VeVLDR_b_OEXV_PressElctrFlt_FltDtct
      VeVLDR_b_OEXV_PressSens_FltDtct: variation-point={short-label=vpVeVLDR_b_OEXV_PressSens_FltDtct, sw-syscond=1}, nonqueued-receiver-com-spec{data-element=Value, init-value=0}, required-interface=VeVLDR_b_OEXV_PressSens_FltDtct
      VeRCVR_e_HTL_Valve_Stuck_State: variation-point={short-label=vpVeRCVR_e_HTL_Valve_Stuck_State, sw-syscond=1}, nonqueued-receiver-com-spec{data-element=Value, init-value=CeRCVR_e_Closed}, required-interface=VeRCVR_e_HTL_Valve_Stuck_State
    46 x provide port:
      VeBTRR_T_CellTempMaxUsed: variation-point={short-label=vpVeBTRR_T_CellTempMaxUsed, sw-syscond=1}, nonqueued-sender-com-spec{data-element=Value, init-value=0}, provided-interface=VeBTRR_T_CellTempMaxUsed
      VeBTRR_T_CellTempMinUsed: variation-point={short-label=vpVeBTRR_T_CellTempMinUsed, sw-syscond=1}, nonqueued-sender-com-spec{data-element=Value, init-value=0}, provided-interface=VeBTRR_T_CellTempMinUsed
      VeBTRR_dT_CellTempDelta: variation-point={short-label=vpVeBTRR_dT_CellTempDelta, sw-syscond=1}, nonqueued-sender-com-spec{data-element=Value, init-value=0}, provided-interface=VeBTRR_dT_CellTempDelta
      VeBTRR_b_HVBR_OvrdReq: variation-point={short-label=vpVeBTRR_b_HVBR_OvrdReq, sw-syscond=1}, nonqueued-sender-com-spec{data-element=Value, init-value=0}, provided-interface=VeBTRR_b_HVBR_OvrdReq
      VeBTRR_b_BattCondFlt: variation-point={short-label=vpVeBTRR_b_BattCondFlt, sw-syscond=1}, nonqueued-sender-com-spec{data-element=Value, init-value=0}, provided-interface=VeBTRR_b_BattCondFlt
      VeBTRR_b_HVBattPriority: variation-point={short-label=vpVeBTRR_b_HVBattPriority, sw-syscond=1}, nonqueued-sender-com-spec{data-element=Value, init-value=0}, provided-interface=VeBTRR_b_HVBattPriority
      VeBTRR_b_BattCoolFlts: variation-point={short-label=vpVeBTRR_b_BattCoolFlts, sw-syscond=1}, nonqueued-sender-com-spec{data-element=Value, init-value=0}, provided-interface=VeBTRR_b_BattCoolFlts
      VeBTRR_T_BTISBTIS2_Max: variation-point={short-label=vpVeBTRR_T_BTISBTIS2_Max, sw-syscond=1}, nonqueued-sender-com-spec{data-element=Value, init-value=0}, provided-interface=VeBTRR_T_BTISBTIS2_Max
      VeBTRR_T_BattDisplayTemp: variation-point={short-label=vpVeBTRR_T_BattDisplayTemp, sw-syscond=1}, nonqueued-sender-com-spec{data-element=Value, init-value=0}, provided-interface=VeBTRR_T_BattDisplayTemp
      VeBTRR_T_BattTmp_MaxDerateZone: variation-point={short-label=vpVeBTRR_T_BattTmp_MaxDerateZone, sw-syscond=1}, nonqueued-sender-com-spec{data-element=Value, init-value=0}, provided-interface=VeBTRR_T_BattTmp_MaxDerateZone
      VeBTRR_T_BattTmp_MinDerateZone: variation-point={short-label=vpVeBTRR_T_BattTmp_MinDerateZone, sw-syscond=1}, nonqueued-sender-com-spec{data-element=Value, init-value=0}, provided-interface=VeBTRR_T_BattTmp_MinDerateZone
      VeBTRR_T_BattTmp_MinCmfrtZone: variation-point={short-label=vpVeBTRR_T_BattTmp_MinCmfrtZone, sw-syscond=1}, nonqueued-sender-com-spec{data-element=Value, init-value=0}, provided-interface=VeBTRR_T_BattTmp_MinCmfrtZone
      VeBTRR_T_BattTmp_MaxCmfrtZone: variation-point={short-label=vpVeBTRR_T_BattTmp_MaxCmfrtZone, sw-syscond=1}, nonqueued-sender-com-spec{data-element=Value, init-value=0}, provided-interface=VeBTRR_T_BattTmp_MaxCmfrtZone
      VeBTRR_b_KeyRun_OV_BattCrit: variation-point={short-label=vpVeBTRR_b_KeyRun_OV_BattCrit, sw-syscond=1}, nonqueued-sender-com-spec{data-element=Value, init-value=0}, provided-interface=VeBTRR_b_KeyRun_OV_BattCrit
      VeBTRR_b_Psv_BattHeatReq: variation-point={short-label=vpVeBTRR_b_Psv_BattHeatReq, sw-syscond=1}, nonqueued-sender-com-spec{data-element=Value, init-value=0}, provided-interface=VeBTRR_b_Psv_BattHeatReq
      VeBTRR_b_BattCoolReq: variation-point={short-label=vpVeBTRR_b_BattCoolReq, sw-syscond=1}, nonqueued-sender-com-spec{data-element=Value, init-value=0}, provided-interface=VeBTRR_b_BattCoolReq
      VeBTRR_b_Batt_PsvCoolReq: variation-point={short-label=vpVeBTRR_b_Batt_PsvCoolReq, sw-syscond=1}, nonqueued-sender-com-spec{data-element=Value, init-value=0}, provided-interface=VeBTRR_b_Batt_PsvCoolReq
      VeBTRR_b_BattCoolReq_CPV_RA: variation-point={short-label=vpVeBTRR_b_BattCoolReq_CPV_RA, sw-syscond=1}, nonqueued-sender-com-spec{data-element=Value, init-value=0}, provided-interface=VeBTRR_b_BattCoolReq_CPV_RA
      VeBTRR_b_BattHeatingFlts: variation-point={short-label=vpVeBTRR_b_BattHeatingFlts, sw-syscond=1}, nonqueued-sender-com-spec{data-element=Value, init-value=0}, provided-interface=VeBTRR_b_BattHeatingFlts
      VeBTRR_T_CellTempAvgUsed: variation-point={short-label=vpVeBTRR_T_CellTempAvgUsed, sw-syscond=1}, nonqueued-sender-com-spec{data-element=Value, init-value=0}, provided-interface=VeBTRR_T_CellTempAvgUsed
      VeBTRR_b_CellTempMaxUsedFA: variation-point={short-label=vpVeBTRR_b_CellTempMaxUsedFA, sw-syscond=1}, nonqueued-sender-com-spec{data-element=Value, init-value=0}, provided-interface=VeBTRR_b_CellTempMaxUsedFA
      VeBTRR_b_CellTempMinUsedFA: variation-point={short-label=vpVeBTRR_b_CellTempMinUsedFA, sw-syscond=1}, nonqueued-sender-com-spec{data-element=Value, init-value=0}, provided-interface=VeBTRR_b_CellTempMinUsedFA
      VeBTRR_b_CellTempAvgUsedFA: variation-point={short-label=vpVeBTRR_b_CellTempAvgUsedFA, sw-syscond=1}, nonqueued-sender-com-spec{data-element=Value, init-value=0}, provided-interface=VeBTRR_b_CellTempAvgUsedFA
      VeBTRR_b_isCharging: variation-point={short-label=vpVeBTRR_b_isCharging, sw-syscond=1}, nonqueued-sender-com-spec{data-element=Value, init-value=0}, provided-interface=VeBTRR_b_isCharging
      VeBTRR_b_BattCondPlugin_Rq: variation-point={short-label=vpVeBTRR_b_BattCondPlugin_Rq, sw-syscond=1}, nonqueued-sender-com-spec{data-element=Value, init-value=0}, provided-interface=VeBTRR_b_BattCondPlugin_Rq
      VeBTRR_b_PlugdIn_Or_Chrg: variation-point={short-label=vpVeBTRR_b_PlugdIn_Or_Chrg, sw-syscond=1}, nonqueued-sender-com-spec{data-element=Value, init-value=0}, provided-interface=VeBTRR_b_PlugdIn_Or_Chrg
      VeBTRR_b_BattCellBalancing: variation-point={short-label=vpVeBTRR_b_BattCellBalancing, sw-syscond=1}, nonqueued-sender-com-spec{data-element=Value, init-value=0}, provided-interface=VeBTRR_b_BattCellBalancing
      VeBTRR_e_HV_BatTmpRng: variation-point={short-label=vpVeBTRR_e_HV_BatTmpRng, sw-syscond=1}, nonqueued-sender-com-spec{data-element=Value, init-value=CeBTRR_e_BatTmpDfltRng}, provided-interface=VeBTRR_e_HV_BatTmpRng
      VeBTRR_b_Batt_CritOrMarg: variation-point={short-label=vpVeBTRR_b_Batt_CritOrMarg, sw-syscond=1}, nonqueued-sender-com-spec{data-element=Value, init-value=0}, provided-interface=VeBTRR_b_Batt_CritOrMarg
      VeBTRR_e_BatCondPriority: variation-point={short-label=vpVeBTRR_e_BatCondPriority, sw-syscond=1}, nonqueued-sender-com-spec{data-element=Value, init-value=CeBTRR_e_BatCond_NoPriority}, provided-interface=VeBTRR_e_BatCondPriority
      VeBTRR_b_BattTempNot_Optml: variation-point={short-label=vpVeBTRR_b_BattTempNot_Optml, sw-syscond=1}, nonqueued-sender-com-spec{data-element=Value, init-value=0}, provided-interface=VeBTRR_b_BattTempNot_Optml
      VeBTRR_b_VhclPlgdIn: variation-point={short-label=vpVeBTRR_b_VhclPlgdIn, sw-syscond=1}, nonqueued-sender-com-spec{data-element=Value, init-value=0}, provided-interface=VeBTRR_b_VhclPlgdIn
      VeBTRR_P_BatHeatPwr_NeedLimtd: variation-point={short-label=vpVeBTRR_P_BatHeatPwr_NeedLimtd, sw-syscond=1}, nonqueued-sender-com-spec{data-element=Value, init-value=0}, provided-interface=VeBTRR_P_BatHeatPwr_NeedLimtd
      VeBTRR_P_BattCoolPwrNeedLim: variation-point={short-label=vpVeBTRR_P_BattCoolPwrNeedLim, sw-syscond=1}, nonqueued-sender-com-spec{data-element=Value, init-value=0}, provided-interface=VeBTRR_P_BattCoolPwrNeedLim
      VeBTRR_b_OoR_Recoverable: variation-point={short-label=vpVeBTRR_b_OoR_Recoverable, sw-syscond=1}, nonqueued-sender-com-spec{data-element=Value, init-value=0}, provided-interface=VeBTRR_b_OoR_Recoverable
      VeBTRR_dT_CellOverTempPsv: variation-point={short-label=vpVeBTRR_dT_CellOverTempPsv, sw-syscond=1}, nonqueued-sender-com-spec{data-element=Value, init-value=0}, provided-interface=VeBTRR_dT_CellOverTempPsv
      VeBTRR_b_ThrmlBatCoolingFlt: variation-point={short-label=vpVeBTRR_b_ThrmlBatCoolingFlt, sw-syscond=1}, nonqueued-sender-com-spec{data-element=Value, init-value=0}, provided-interface=VeBTRR_b_ThrmlBatCoolingFlt
      VeBTRR_T_HV_BatModTempMax: variation-point={short-label=vpVeBTRR_T_HV_BatModTempMax, sw-syscond=1}, nonqueued-sender-com-spec{data-element=Value, init-value=0}, provided-interface=VeBTRR_T_HV_BatModTempMax
      VeBTRR_T_HV_BatModTempMin: variation-point={short-label=vpVeBTRR_T_HV_BatModTempMin, sw-syscond=1}, nonqueued-sender-com-spec{data-element=Value, init-value=0}, provided-interface=VeBTRR_T_HV_BatModTempMin
      VeBTRR_dT_CellUnderTemp: variation-point={short-label=vpVeBTRR_dT_CellUnderTemp, sw-syscond=1}, nonqueued-sender-com-spec{data-element=Value, init-value=0}, provided-interface=VeBTRR_dT_CellUnderTemp
      VeBTRR_dT_CellOverTemp: variation-point={short-label=vpVeBTRR_dT_CellOverTemp, sw-syscond=1}, nonqueued-sender-com-spec{data-element=Value, init-value=0}, provided-interface=VeBTRR_dT_CellOverTemp
      VeBTRR_dV_LT_ActPmpFlw: variation-point={short-label=vpVeBTRR_dV_LT_ActPmpFlw, sw-syscond=1}, nonqueued-sender-com-spec{data-element=Value, init-value=0}, provided-interface=VeBTRR_dV_LT_ActPmpFlw
      VeBTRR_b_PerWup_BatToCond: variation-point={short-label=vpVeBTRR_b_PerWup_BatToCond, sw-syscond=1}, nonqueued-sender-com-spec{data-element=Value, init-value=0}, provided-interface=VeBTRR_b_PerWup_BatToCond
      VeBTRR_b_HV_BatTempCrit_Cond: variation-point={short-label=vpVeBTRR_b_HV_BatTempCrit_Cond, sw-syscond=1}, nonqueued-sender-com-spec{data-element=Value, init-value=0}, provided-interface=VeBTRR_b_HV_BatTempCrit_Cond
      VeBTRR_e_HV_BatTempCrit_CondState_New: variation-point={short-label=vpVeBTRR_e_HV_BatTempCrit_CondState_New, sw-syscond=1}, nonqueued-sender-com-spec{data-element=Value, init-value=CeBTRR_e_BatNotCrit}, provided-interface=VeBTRR_e_HV_BatTempCrit_CondState_New
      VeBTRR_b_BattHeatReq: variation-point={short-label=vpVeBTRR_b_BattHeatReq, sw-syscond=1}, nonqueued-sender-com-spec{data-element=Value, init-value=0}, provided-interface=VeBTRR_b_BattHeatReq
    behavior IB_BTRR: data-type-mapping=msADTtoIDTMapping, handle-termination-and-restart=NO-SUPPORT
      timing event Event_FastTEF: start-on-event=BTRR_FastTEF, period=0.005
      timing event Event_MedTEH: start-on-event=BTRR_MedTEH, period=0.1
      init event Event_BTRR_ac_Init: start-on-event=BTRR_ac_Init
      init event Event_PwrOn: start-on-event=BTRR_PwrOn
      explicit-inter-runnable-variables:
        13 x data, all with category=VALUE, sw-calibration-access=READ-ONLY, init-value=0:
          CellTempMinUsed_write_IRV: type=Float, variation-point={short-label=vpCellTempMinUsed_write_IRV, sw-syscond=1}
          CellTempMaxUsed_write_IRV: type=Float, variation-point={short-label=vpCellTempMaxUsed_write_IRV, sw-syscond=1}
          HV_BatClntTmp_In_AftDial_write_IRV: type=Float, variation-point={short-label=vpHV_BatClntTmp_In_AftDial_write_IRV, sw-syscond=1}
          BatTmpHys_ColdRgHgh_D_write_IRV: type=Float, variation-point={short-label=vpBatTmpHys_ColdRgHgh_D_write_IRV, sw-syscond=1}
          BatTmpHys_ColdRgLw_D_write_IRV: type=Float, variation-point={short-label=vpBatTmpHys_ColdRgLw_D_write_IRV, sw-syscond=1}
          BatTmpCold_RgHgh_D_write_IRV: type=Float, variation-point={short-label=vpBatTmpCold_RgHgh_D_write_IRV, sw-syscond=1}
          BatTmpCold_RgLw_D_write_IRV: type=Float, variation-point={short-label=vpBatTmpCold_RgLw_D_write_IRV, sw-syscond=1}
          CellTempDelta_write_IRV: type=Float, variation-point={short-label=vpCellTempDelta_write_IRV, sw-syscond=1}
          HVBR_Ovrd_Req_write_IRV: type=Boolean, variation-point={short-label=vpHVBR_Ovrd_Req_write_IRV, sw-syscond=1}
          PropSysActv_BTRR_AftDial_write_IRV: type=Boolean, variation-point={short-label=vpPropSysActv_BTRR_AftDial_write_IRV, sw-syscond=1}
          CellTempMaxFA_write_IRV: type=Boolean, variation-point={short-label=vpCellTempMaxFA_write_IRV, sw-syscond=1}
          CellTempMinFA_write_IRV: type=Boolean, variation-point={short-label=vpCellTempMinFA_write_IRV, sw-syscond=1}
          CellTempDelta_Raw_write_IRV: type=Float, variation-point={short-label=vpCellTempDelta_Raw_write_IRV, sw-syscond=1}
      4 x runnable:
        BTRR_ac_Init
          data-send-points:
            access OUT_VeBTRR_e_HV_BatTmpRng_Value: accessed-variable=VeBTRR_e_HV_BatTmpRng.Value, variation-point={short-label=vpOUT_VeBTRR_e_HV_BatTmpRng_Value, sw-syscond=1}
            access OUT_VeBTRR_e_BatCondPriority_Value: accessed-variable=VeBTRR_e_BatCondPriority.Value, variation-point={short-label=vpOUT_VeBTRR_e_BatCondPriority_Value, sw-syscond=1}
            access OUT_VeBTRR_e_HV_BatTempCrit_CondState_New_Value: accessed-variable=VeBTRR_e_HV_BatTempCrit_CondState_New.Value, variation-point={short-label=vpOUT_VeBTRR_e_HV_BatTempCrit_CondState_New_Value, sw-syscond=1}
        BTRR_PwrOn
          data-send-points:
            46 x access:
              OUT_VeBTRR_T_CellTempMaxUsed_Value: accessed-variable=VeBTRR_T_CellTempMaxUsed.Value, variation-point={short-label=vpOUT_VeBTRR_T_CellTempMaxUsed_Value, sw-syscond=1}
              OUT_VeBTRR_T_CellTempMinUsed_Value: accessed-variable=VeBTRR_T_CellTempMinUsed.Value, variation-point={short-label=vpOUT_VeBTRR_T_CellTempMinUsed_Value, sw-syscond=1}
              OUT_VeBTRR_b_BattHeatReq_Value: accessed-variable=VeBTRR_b_BattHeatReq.Value, variation-point={short-label=vpOUT_VeBTRR_b_BattHeatReq_Value, sw-syscond=1}
              OUT_VeBTRR_b_isCharging_Value: accessed-variable=VeBTRR_b_isCharging.Value, variation-point={short-label=vpOUT_VeBTRR_b_isCharging_Value, sw-syscond=1}
              OUT_VeBTRR_b_BattCondPlugin_Rq_Value: accessed-variable=VeBTRR_b_BattCondPlugin_Rq.Value, variation-point={short-label=vpOUT_VeBTRR_b_BattCondPlugin_Rq_Value, sw-syscond=1}
              OUT_VeBTRR_b_PlugdIn_Or_Chrg_Value: accessed-variable=VeBTRR_b_PlugdIn_Or_Chrg.Value, variation-point={short-label=vpOUT_VeBTRR_b_PlugdIn_Or_Chrg_Value, sw-syscond=1}
              OUT_VeBTRR_b_OoR_Recoverable_Value: accessed-variable=VeBTRR_b_OoR_Recoverable.Value, variation-point={short-label=vpOUT_VeBTRR_b_OoR_Recoverable_Value, sw-syscond=1}
              OUT_VeBTRR_dT_CellOverTempPsv_Value: accessed-variable=VeBTRR_dT_CellOverTempPsv.Value, variation-point={short-label=vpOUT_VeBTRR_dT_CellOverTempPsv_Value, sw-syscond=1}
              OUT_VeBTRR_b_BattCellBalancing_Value: accessed-variable=VeBTRR_b_BattCellBalancing.Value, variation-point={short-label=vpOUT_VeBTRR_b_BattCellBalancing_Value, sw-syscond=1}
              OUT_VeBTRR_e_HV_BatTmpRng_Value: accessed-variable=VeBTRR_e_HV_BatTmpRng.Value, variation-point={short-label=vpOUT_VeBTRR_e_HV_BatTmpRng_Value, sw-syscond=1}
              OUT_VeBTRR_b_Batt_CritOrMarg_Value: accessed-variable=VeBTRR_b_Batt_CritOrMarg.Value, variation-point={short-label=vpOUT_VeBTRR_b_Batt_CritOrMarg_Value, sw-syscond=1}
              OUT_VeBTRR_e_BatCondPriority_Value: accessed-variable=VeBTRR_e_BatCondPriority.Value, variation-point={short-label=vpOUT_VeBTRR_e_BatCondPriority_Value, sw-syscond=1}
              OUT_VeBTRR_dT_CellTempDelta_Value: accessed-variable=VeBTRR_dT_CellTempDelta.Value, variation-point={short-label=vpOUT_VeBTRR_dT_CellTempDelta_Value, sw-syscond=1}
              OUT_VeBTRR_b_BattTempNot_Optml_Value: accessed-variable=VeBTRR_b_BattTempNot_Optml.Value, variation-point={short-label=vpOUT_VeBTRR_b_BattTempNot_Optml_Value, sw-syscond=1}
              OUT_VeBTRR_b_VhclPlgdIn_Value: accessed-variable=VeBTRR_b_VhclPlgdIn.Value, variation-point={short-label=vpOUT_VeBTRR_b_VhclPlgdIn_Value, sw-syscond=1}
              OUT_VeBTRR_P_BatHeatPwr_NeedLimtd_Value: accessed-variable=VeBTRR_P_BatHeatPwr_NeedLimtd.Value, variation-point={short-label=vpOUT_VeBTRR_P_BatHeatPwr_NeedLimtd_Value, sw-syscond=1}
              OUT_VeBTRR_P_BattCoolPwrNeedLim_Value: accessed-variable=VeBTRR_P_BattCoolPwrNeedLim.Value, variation-point={short-label=vpOUT_VeBTRR_P_BattCoolPwrNeedLim_Value, sw-syscond=1}
              OUT_VeBTRR_b_ThrmlBatCoolingFlt_Value: accessed-variable=VeBTRR_b_ThrmlBatCoolingFlt.Value, variation-point={short-label=vpOUT_VeBTRR_b_ThrmlBatCoolingFlt_Value, sw-syscond=1}
              OUT_VeBTRR_T_CellTempAvgUsed_Value: accessed-variable=VeBTRR_T_CellTempAvgUsed.Value, variation-point={short-label=vpOUT_VeBTRR_T_CellTempAvgUsed_Value, sw-syscond=1}
              OUT_VeBTRR_T_BTISBTIS2_Max_Value: accessed-variable=VeBTRR_T_BTISBTIS2_Max.Value, variation-point={short-label=vpOUT_VeBTRR_T_BTISBTIS2_Max_Value, sw-syscond=1}
              OUT_VeBTRR_T_BattDisplayTemp_Value: accessed-variable=VeBTRR_T_BattDisplayTemp.Value, variation-point={short-label=vpOUT_VeBTRR_T_BattDisplayTemp_Value, sw-syscond=1}
              OUT_VeBTRR_b_CellTempMaxUsedFA_Value: accessed-variable=VeBTRR_b_CellTempMaxUsedFA.Value, variation-point={short-label=vpOUT_VeBTRR_b_CellTempMaxUsedFA_Value, sw-syscond=1}
              OUT_VeBTRR_b_CellTempMinUsedFA_Value: accessed-variable=VeBTRR_b_CellTempMinUsedFA.Value, variation-point={short-label=vpOUT_VeBTRR_b_CellTempMinUsedFA_Value, sw-syscond=1}
              OUT_VeBTRR_b_HVBR_OvrdReq_Value: accessed-variable=VeBTRR_b_HVBR_OvrdReq.Value, variation-point={short-label=vpOUT_VeBTRR_b_HVBR_OvrdReq_Value, sw-syscond=1}
              OUT_VeBTRR_b_CellTempAvgUsedFA_Value: accessed-variable=VeBTRR_b_CellTempAvgUsedFA.Value, variation-point={short-label=vpOUT_VeBTRR_b_CellTempAvgUsedFA_Value, sw-syscond=1}
              OUT_VeBTRR_b_BattCondFlt_Value: accessed-variable=VeBTRR_b_BattCondFlt.Value, variation-point={short-label=vpOUT_VeBTRR_b_BattCondFlt_Value, sw-syscond=1}
              OUT_VeBTRR_b_HVBattPriority_Value: accessed-variable=VeBTRR_b_HVBattPriority.Value, variation-point={short-label=vpOUT_VeBTRR_b_HVBattPriority_Value, sw-syscond=1}
              OUT_VeBTRR_b_BattCoolFlts_Value: accessed-variable=VeBTRR_b_BattCoolFlts.Value, variation-point={short-label=vpOUT_VeBTRR_b_BattCoolFlts_Value, sw-syscond=1}
              OUT_VeBTRR_T_HV_BatModTempMax_Value: accessed-variable=VeBTRR_T_HV_BatModTempMax.Value, variation-point={short-label=vpOUT_VeBTRR_T_HV_BatModTempMax_Value, sw-syscond=1}
              OUT_VeBTRR_T_HV_BatModTempMin_Value: accessed-variable=VeBTRR_T_HV_BatModTempMin.Value, variation-point={short-label=vpOUT_VeBTRR_T_HV_BatModTempMin_Value, sw-syscond=1}
              OUT_VeBTRR_b_KeyRun_OV_BattCrit_Value: accessed-variable=VeBTRR_b_KeyRun_OV_BattCrit.Value, variation-point={short-label=vpOUT_VeBTRR_b_KeyRun_OV_BattCrit_Value, sw-syscond=1}
              OUT_VeBTRR_b_Psv_BattHeatReq_Value: accessed-variable=VeBTRR_b_Psv_BattHeatReq.Value, variation-point={short-label=vpOUT_VeBTRR_b_Psv_BattHeatReq_Value, sw-syscond=1}
              OUT_VeBTRR_T_BattTmp_MaxDerateZone_Value: accessed-variable=VeBTRR_T_BattTmp_MaxDerateZone.Value, variation-point={short-label=vpOUT_VeBTRR_T_BattTmp_MaxDerateZone_Value, sw-syscond=1}
              OUT_VeBTRR_T_BattTmp_MinDerateZone_Value: accessed-variable=VeBTRR_T_BattTmp_MinDerateZone.Value, variation-point={short-label=vpOUT_VeBTRR_T_BattTmp_MinDerateZone_Value, sw-syscond=1}
              OUT_VeBTRR_dT_CellUnderTemp_Value: accessed-variable=VeBTRR_dT_CellUnderTemp.Value, variation-point={short-label=vpOUT_VeBTRR_dT_CellUnderTemp_Value, sw-syscond=1}
              OUT_VeBTRR_T_BattTmp_MinCmfrtZone_Value: accessed-variable=VeBTRR_T_BattTmp_MinCmfrtZone.Value, variation-point={short-label=vpOUT_VeBTRR_T_BattTmp_MinCmfrtZone_Value, sw-syscond=1}
              OUT_VeBTRR_T_BattTmp_MaxCmfrtZone_Value: accessed-variable=VeBTRR_T_BattTmp_MaxCmfrtZone.Value, variation-point={short-label=vpOUT_VeBTRR_T_BattTmp_MaxCmfrtZone_Value, sw-syscond=1}
              OUT_VeBTRR_b_BattCoolReq_Value: accessed-variable=VeBTRR_b_BattCoolReq.Value, variation-point={short-label=vpOUT_VeBTRR_b_BattCoolReq_Value, sw-syscond=1}
              OUT_VeBTRR_b_Batt_PsvCoolReq_Value: accessed-variable=VeBTRR_b_Batt_PsvCoolReq.Value, variation-point={short-label=vpOUT_VeBTRR_b_Batt_PsvCoolReq_Value, sw-syscond=1}
              OUT_VeBTRR_b_BattCoolReq_CPV_RA_Value: accessed-variable=VeBTRR_b_BattCoolReq_CPV_RA.Value, variation-point={short-label=vpOUT_VeBTRR_b_BattCoolReq_CPV_RA_Value, sw-syscond=1}
              OUT_VeBTRR_b_BattHeatingFlts_Value: accessed-variable=VeBTRR_b_BattHeatingFlts.Value, variation-point={short-label=vpOUT_VeBTRR_b_BattHeatingFlts_Value, sw-syscond=1}
              OUT_VeBTRR_dT_CellOverTemp_Value: accessed-variable=VeBTRR_dT_CellOverTemp.Value, variation-point={short-label=vpOUT_VeBTRR_dT_CellOverTemp_Value, sw-syscond=1}
              OUT_VeBTRR_dV_LT_ActPmpFlw_Value: accessed-variable=VeBTRR_dV_LT_ActPmpFlw.Value, variation-point={short-label=vpOUT_VeBTRR_dV_LT_ActPmpFlw_Value, sw-syscond=1}
              OUT_VeBTRR_b_PerWup_BatToCond_Value: accessed-variable=VeBTRR_b_PerWup_BatToCond.Value, variation-point={short-label=vpOUT_VeBTRR_b_PerWup_BatToCond_Value, sw-syscond=1}
              OUT_VeBTRR_b_HV_BatTempCrit_Cond_Value: accessed-variable=VeBTRR_b_HV_BatTempCrit_Cond.Value, variation-point={short-label=vpOUT_VeBTRR_b_HV_BatTempCrit_Cond_Value, sw-syscond=1}
              OUT_VeBTRR_e_HV_BatTempCrit_CondState_New_Value: accessed-variable=VeBTRR_e_HV_BatTempCrit_CondState_New.Value, variation-point={short-label=vpOUT_VeBTRR_e_HV_BatTempCrit_CondState_New_Value, sw-syscond=1}
          written-local-variables:
            13 x access:
              WV_BatTmpCold_RgHgh_D_write_IRV: accessed-variable=BatTmpCold_RgHgh_D_write_IRV, variation-point={short-label=vpWV_BatTmpCold_RgHgh_D_write_IRV, sw-syscond=1}
              WV_BatTmpCold_RgLw_D_write_IRV: accessed-variable=BatTmpCold_RgLw_D_write_IRV, variation-point={short-label=vpWV_BatTmpCold_RgLw_D_write_IRV, sw-syscond=1}
              WV_BatTmpHys_ColdRgHgh_D_write_IRV: accessed-variable=BatTmpHys_ColdRgHgh_D_write_IRV, variation-point={short-label=vpWV_BatTmpHys_ColdRgHgh_D_write_IRV, sw-syscond=1}
              WV_BatTmpHys_ColdRgLw_D_write_IRV: accessed-variable=BatTmpHys_ColdRgLw_D_write_IRV, variation-point={short-label=vpWV_BatTmpHys_ColdRgLw_D_write_IRV, sw-syscond=1}
              WV_CellTempDelta_Raw_write_IRV: accessed-variable=CellTempDelta_Raw_write_IRV, variation-point={short-label=vpWV_CellTempDelta_Raw_write_IRV, sw-syscond=1}
              WV_CellTempDelta_write_IRV: accessed-variable=CellTempDelta_write_IRV, variation-point={short-label=vpWV_CellTempDelta_write_IRV, sw-syscond=1}
              WV_CellTempMaxFA_write_IRV: accessed-variable=CellTempMaxFA_write_IRV, variation-point={short-label=vpWV_CellTempMaxFA_write_IRV, sw-syscond=1}
              WV_CellTempMaxUsed_write_IRV: accessed-variable=CellTempMaxUsed_write_IRV, variation-point={short-label=vpWV_CellTempMaxUsed_write_IRV, sw-syscond=1}
              WV_CellTempMinFA_write_IRV: accessed-variable=CellTempMinFA_write_IRV, variation-point={short-label=vpWV_CellTempMinFA_write_IRV, sw-syscond=1}
              WV_CellTempMinUsed_write_IRV: accessed-variable=CellTempMinUsed_write_IRV, variation-point={short-label=vpWV_CellTempMinUsed_write_IRV, sw-syscond=1}
              WV_HVBR_Ovrd_Req_write_IRV: accessed-variable=HVBR_Ovrd_Req_write_IRV, variation-point={short-label=vpWV_HVBR_Ovrd_Req_write_IRV, sw-syscond=1}
              WV_HV_BatClntTmp_In_AftDial_write_IRV: accessed-variable=HV_BatClntTmp_In_AftDial_write_IRV, variation-point={short-label=vpWV_HV_BatClntTmp_In_AftDial_write_IRV, sw-syscond=1}
              WV_PropSysActv_BTRR_AftDial_write_IRV: accessed-variable=PropSysActv_BTRR_AftDial_write_IRV, variation-point={short-label=vpWV_PropSysActv_BTRR_AftDial_write_IRV, sw-syscond=1}
        BTRR_FastTEF: variation-point={short-label=vpBTRR_FastTEF, sw-syscond=1}
          data-receive-point-by-arguments:
            13 x access:
              IN_VeBPCR_T_HV_BatModTempAvg_Value: accessed-variable=VeBPCR_T_HV_BatModTempAvg.Value, variation-point={short-label=vpIN_VeBPCR_T_HV_BatModTempAvg_Value, sw-syscond=1}
              IN_VeBPCR_T_HV_BatModTempMax_Value: accessed-variable=VeBPCR_T_HV_BatModTempMax.Value, variation-point={short-label=vpIN_VeBPCR_T_HV_BatModTempMax_Value, sw-syscond=1}
              IN_VeBPCR_T_HV_BatModTempMin_Value: accessed-variable=VeBPCR_T_HV_BatModTempMin.Value, variation-point={short-label=vpIN_VeBPCR_T_HV_BatModTempMin_Value, sw-syscond=1}
              IN_VeBPCR_b_HV_BatModTempAvgFA_Value: accessed-variable=VeBPCR_b_HV_BatModTempAvgFA.Value, variation-point={short-label=vpIN_VeBPCR_b_HV_BatModTempAvgFA_Value, sw-syscond=1}
              IN_VeBPCR_b_HV_BatModTempMaxFA_Value: accessed-variable=VeBPCR_b_HV_BatModTempMaxFA.Value, variation-point={short-label=vpIN_VeBPCR_b_HV_BatModTempMaxFA_Value, sw-syscond=1}
              IN_VeBPCR_b_HV_BatModTempMinFA_Value: accessed-variable=VeBPCR_b_HV_BatModTempMinFA.Value, variation-point={short-label=vpIN_VeBPCR_b_HV_BatModTempMinFA_Value, sw-syscond=1}
              IN_VeDMAB_y_StatusByte_MtrElect_CoolPmpATempSnsrPerf_Value: accessed-variable=VeDMAB_y_StatusByte_MtrElect_CoolPmpATempSnsrPerf.Value, variation-point={short-label=vpIN_VeDMAB_y_StatusByte_MtrElect_CoolPmpATempSnsrPerf_Value, sw-syscond=1}
              IN_VeHPMR_b_PropSysActv_Value: accessed-variable=VeHPMR_b_PropSysActv.Value, variation-point={short-label=vpIN_VeHPMR_b_PropSysActv_Value, sw-syscond=1}
              IN_VePMIR_T_HTAuxPumpTemp_Value: accessed-variable=VePMIR_T_HTAuxPumpTemp.Value, variation-point={short-label=vpIN_VePMIR_T_HTAuxPumpTemp_Value, sw-syscond=1}
              IN_VePMIR_T_LTPsvPumpTemp_Value: accessed-variable=VePMIR_T_LTPsvPumpTemp.Value, variation-point={short-label=vpIN_VePMIR_T_LTPsvPumpTemp_Value, sw-syscond=1}
              IN_VePMIR_b_HTAuxPumpTemp_FA_Value: accessed-variable=VePMIR_b_HTAuxPumpTemp_FA.Value, variation-point={short-label=vpIN_VePMIR_b_HTAuxPumpTemp_FA_Value, sw-syscond=1}
              IN_VeTMIR_T_PsvPmpClnt_TmpIn_Value: accessed-variable=VeTMIR_T_PsvPmpClnt_TmpIn.Value, variation-point={short-label=vpIN_VeTMIR_T_PsvPmpClnt_TmpIn_Value, sw-syscond=1}
              IN_VeTRIR_T_HV_BatClntTmp_In_Value: accessed-variable=VeTRIR_T_HV_BatClntTmp_In.Value, variation-point={short-label=vpIN_VeTRIR_T_HV_BatClntTmp_In_Value, sw-syscond=1}
          data-send-points:
            10 x access:
              OUT_VeBTRR_T_CellTempMaxUsed_Value: accessed-variable=VeBTRR_T_CellTempMaxUsed.Value, variation-point={short-label=vpOUT_VeBTRR_T_CellTempMaxUsed_Value, sw-syscond=1}
              OUT_VeBTRR_T_CellTempMinUsed_Value: accessed-variable=VeBTRR_T_CellTempMinUsed.Value, variation-point={short-label=vpOUT_VeBTRR_T_CellTempMinUsed_Value, sw-syscond=1}
              OUT_VeBTRR_dT_CellTempDelta_Value: accessed-variable=VeBTRR_dT_CellTempDelta.Value, variation-point={short-label=vpOUT_VeBTRR_dT_CellTempDelta_Value, sw-syscond=1}
              OUT_VeBTRR_T_CellTempAvgUsed_Value: accessed-variable=VeBTRR_T_CellTempAvgUsed.Value, variation-point={short-label=vpOUT_VeBTRR_T_CellTempAvgUsed_Value, sw-syscond=1}
              OUT_VeBTRR_b_CellTempMaxUsedFA_Value: accessed-variable=VeBTRR_b_CellTempMaxUsedFA.Value, variation-point={short-label=vpOUT_VeBTRR_b_CellTempMaxUsedFA_Value, sw-syscond=1}
              OUT_VeBTRR_b_CellTempMinUsedFA_Value: accessed-variable=VeBTRR_b_CellTempMinUsedFA.Value, variation-point={short-label=vpOUT_VeBTRR_b_CellTempMinUsedFA_Value, sw-syscond=1}
              OUT_VeBTRR_b_HVBR_OvrdReq_Value: accessed-variable=VeBTRR_b_HVBR_OvrdReq.Value, variation-point={short-label=vpOUT_VeBTRR_b_HVBR_OvrdReq_Value, sw-syscond=1}
              OUT_VeBTRR_b_CellTempAvgUsedFA_Value: accessed-variable=VeBTRR_b_CellTempAvgUsedFA.Value, variation-point={short-label=vpOUT_VeBTRR_b_CellTempAvgUsedFA_Value, sw-syscond=1}
              OUT_VeBTRR_T_HV_BatModTempMax_Value: accessed-variable=VeBTRR_T_HV_BatModTempMax.Value, variation-point={short-label=vpOUT_VeBTRR_T_HV_BatModTempMax_Value, sw-syscond=1}
              OUT_VeBTRR_T_HV_BatModTempMin_Value: accessed-variable=VeBTRR_T_HV_BatModTempMin.Value, variation-point={short-label=vpOUT_VeBTRR_T_HV_BatModTempMin_Value, sw-syscond=1}
          written-local-variables:
            13 x access:
              WV_BatTmpCold_RgHgh_D_write_IRV: accessed-variable=BatTmpCold_RgHgh_D_write_IRV, variation-point={short-label=vpWV_BatTmpCold_RgHgh_D_write_IRV, sw-syscond=1}
              WV_BatTmpCold_RgLw_D_write_IRV: accessed-variable=BatTmpCold_RgLw_D_write_IRV, variation-point={short-label=vpWV_BatTmpCold_RgLw_D_write_IRV, sw-syscond=1}
              WV_BatTmpHys_ColdRgHgh_D_write_IRV: accessed-variable=BatTmpHys_ColdRgHgh_D_write_IRV, variation-point={short-label=vpWV_BatTmpHys_ColdRgHgh_D_write_IRV, sw-syscond=1}
              WV_BatTmpHys_ColdRgLw_D_write_IRV: accessed-variable=BatTmpHys_ColdRgLw_D_write_IRV, variation-point={short-label=vpWV_BatTmpHys_ColdRgLw_D_write_IRV, sw-syscond=1}
              WV_CellTempDelta_Raw_write_IRV: accessed-variable=CellTempDelta_Raw_write_IRV, variation-point={short-label=vpWV_CellTempDelta_Raw_write_IRV, sw-syscond=1}
              WV_CellTempDelta_write_IRV: accessed-variable=CellTempDelta_write_IRV, variation-point={short-label=vpWV_CellTempDelta_write_IRV, sw-syscond=1}
              WV_CellTempMaxFA_write_IRV: accessed-variable=CellTempMaxFA_write_IRV, variation-point={short-label=vpWV_CellTempMaxFA_write_IRV, sw-syscond=1}
              WV_CellTempMaxUsed_write_IRV: accessed-variable=CellTempMaxUsed_write_IRV, variation-point={short-label=vpWV_CellTempMaxUsed_write_IRV, sw-syscond=1}
              WV_CellTempMinFA_write_IRV: accessed-variable=CellTempMinFA_write_IRV, variation-point={short-label=vpWV_CellTempMinFA_write_IRV, sw-syscond=1}
              WV_CellTempMinUsed_write_IRV: accessed-variable=CellTempMinUsed_write_IRV, variation-point={short-label=vpWV_CellTempMinUsed_write_IRV, sw-syscond=1}
              WV_HVBR_Ovrd_Req_write_IRV: accessed-variable=HVBR_Ovrd_Req_write_IRV, variation-point={short-label=vpWV_HVBR_Ovrd_Req_write_IRV, sw-syscond=1}
              WV_HV_BatClntTmp_In_AftDial_write_IRV: accessed-variable=HV_BatClntTmp_In_AftDial_write_IRV, variation-point={short-label=vpWV_HV_BatClntTmp_In_AftDial_write_IRV, sw-syscond=1}
              WV_PropSysActv_BTRR_AftDial_write_IRV: accessed-variable=PropSysActv_BTRR_AftDial_write_IRV, variation-point={short-label=vpWV_PropSysActv_BTRR_AftDial_write_IRV, sw-syscond=1}
        BTRR_MedTEH: variation-point={short-label=vpBTRR_MedTEH, sw-syscond=1}
          data-receive-point-by-arguments:
            127 x access:
              IN_VeAATR_T_EstAmbAirTemp_Value: accessed-variable=VeAATR_T_EstAmbAirTemp.Value, variation-point={short-label=vpIN_VeAATR_T_EstAmbAirTemp_Value, sw-syscond=1}
              IN_VeAVTR_T_SDS_Clnt_TmpIn_Act_Value: accessed-variable=VeAVTR_T_SDS_Clnt_TmpIn_Act.Value, variation-point={short-label=vpIN_VeAVTR_T_SDS_Clnt_TmpIn_Act_Value, sw-syscond=1}
              IN_VeAVTR_dT_SDS_ClntTempErr_Value: accessed-variable=VeAVTR_dT_SDS_ClntTempErr.Value, variation-point={short-label=vpIN_VeAVTR_dT_SDS_ClntTempErr_Value, sw-syscond=1}
              IN_VeAVTR_e_EVA_ThrmlState_Value: accessed-variable=VeAVTR_e_EVA_ThrmlState.Value, variation-point={short-label=vpIN_VeAVTR_e_EVA_ThrmlState_Value, sw-syscond=1}
              IN_VeAVTR_e_SDS_Actual_State_Value: accessed-variable=VeAVTR_e_SDS_Actual_State.Value, variation-point={short-label=vpIN_VeAVTR_e_SDS_Actual_State_Value, sw-syscond=1}
              IN_VeBPCR_b_BPCM_LIN_BusOff_FA_Value: accessed-variable=VeBPCR_b_BPCM_LIN_BusOff_FA.Value, variation-point={short-label=vpIN_VeBPCR_b_BPCM_LIN_BusOff_FA_Value, sw-syscond=1}
              IN_VeBPCR_b_BPCM_LOC_BCP_FA_Value: accessed-variable=VeBPCR_b_BPCM_LOC_BCP_FA.Value, variation-point={short-label=vpIN_VeBPCR_b_BPCM_LOC_BCP_FA_Value, sw-syscond=1}
              IN_VeBPCR_b_BPCM_LOC_BatClntHtr_FA_Value: accessed-variable=VeBPCR_b_BPCM_LOC_BatClntHtr_FA.Value, variation-point={short-label=vpIN_VeBPCR_b_BPCM_LOC_BatClntHtr_FA_Value, sw-syscond=1}
              IN_VeBPCR_b_BPCM_OVActv_Value: accessed-variable=VeBPCR_b_BPCM_OVActv.Value, variation-point={short-label=vpIN_VeBPCR_b_BPCM_OVActv_Value, sw-syscond=1}
              IN_VeBPCR_e_BPCM_LIN_BusOff_Value: accessed-variable=VeBPCR_e_BPCM_LIN_BusOff.Value, variation-point={short-label=vpIN_VeBPCR_e_BPCM_LIN_BusOff_Value, sw-syscond=1}
              IN_VeBPCR_e_BPCM_LOC_BCP_Value: accessed-variable=VeBPCR_e_BPCM_LOC_BCP.Value, variation-point={short-label=vpIN_VeBPCR_e_BPCM_LOC_BCP_Value, sw-syscond=1}
              IN_VeBPCR_e_BPCM_LOC_BatClntHtr_Value: accessed-variable=VeBPCR_e_BPCM_LOC_BatClntHtr.Value, variation-point={short-label=vpIN_VeBPCR_e_BPCM_LOC_BatClntHtr_Value, sw-syscond=1}
              IN_VeBPCR_e_HV_BatCntctrStat_Value: accessed-variable=VeBPCR_e_HV_BatCntctrStat.Value, variation-point={short-label=vpIN_VeBPCR_e_HV_BatCntctrStat_Value, sw-syscond=1}
              IN_VeBRDR_b_HV_BTIS2_FltDtct_Value: accessed-variable=VeBRDR_b_HV_BTIS2_FltDtct.Value, variation-point={short-label=vpIN_VeBRDR_b_HV_BTIS2_FltDtct_Value, sw-syscond=1}
              IN_VeBRDR_b_HV_BTIS_FltDtct_Value: accessed-variable=VeBRDR_b_HV_BTIS_FltDtct.Value, variation-point={short-label=vpIN_VeBRDR_b_HV_BTIS_FltDtct_Value, sw-syscond=1}
              IN_VeBRDR_b_HV_BTOS2_FltDtct_Value: accessed-variable=VeBRDR_b_HV_BTOS2_FltDtct.Value, variation-point={short-label=vpIN_VeBRDR_b_HV_BTOS2_FltDtct_Value, sw-syscond=1}
              IN_VeBRDR_b_LTAP_Rqt_LoLv_Diag_Value: accessed-variable=VeBRDR_b_LTAP_Rqt_LoLv_Diag.Value, variation-point={short-label=vpIN_VeBRDR_b_LTAP_Rqt_LoLv_Diag_Value, sw-syscond=1}
              IN_VeDMAB_y_StatusByte_AC_RefrigPresSnsrAHi_Value: accessed-variable=VeDMAB_y_StatusByte_AC_RefrigPresSnsrAHi.Value, variation-point={short-label=vpIN_VeDMAB_y_StatusByte_AC_RefrigPresSnsrAHi_Value, sw-syscond=1}
              IN_VeDMAB_y_StatusByte_AC_RefrigPresSnsrALo_Value: accessed-variable=VeDMAB_y_StatusByte_AC_RefrigPresSnsrALo.Value, variation-point={short-label=vpIN_VeDMAB_y_StatusByte_AC_RefrigPresSnsrALo_Value, sw-syscond=1}
              IN_VeDMAB_y_StatusByte_AC_RefrigPresSnsrAPerf_Value: accessed-variable=VeDMAB_y_StatusByte_AC_RefrigPresSnsrAPerf.Value, variation-point={short-label=vpIN_VeDMAB_y_StatusByte_AC_RefrigPresSnsrAPerf_Value, sw-syscond=1}
              IN_VeDMAB_y_StatusByte_AC_RefrigTempSnsr4CktPerf_Value: accessed-variable=VeDMAB_y_StatusByte_AC_RefrigTempSnsr4CktPerf.Value, variation-point={short-label=vpIN_VeDMAB_y_StatusByte_AC_RefrigTempSnsr4CktPerf_Value, sw-syscond=1}
              IN_VeDMAB_y_StatusByte_AC_RefrigTempSnsr5CktPerf_Value: accessed-variable=VeDMAB_y_StatusByte_AC_RefrigTempSnsr5CktPerf.Value, variation-point={short-label=vpIN_VeDMAB_y_StatusByte_AC_RefrigTempSnsr5CktPerf_Value, sw-syscond=1}
              IN_VeDMAB_y_StatusByte_AC_RefrigTempSnsr5CktShotoBat_Value: accessed-variable=VeDMAB_y_StatusByte_AC_RefrigTempSnsr5CktShotoBat.Value, variation-point={short-label=vpIN_VeDMAB_y_StatusByte_AC_RefrigTempSnsr5CktShotoBat_Value, sw-syscond=1}
              IN_VeDMAB_y_StatusByte_AC_RefrigTempSnsr5CktShotoGro_Value: accessed-variable=VeDMAB_y_StatusByte_AC_RefrigTempSnsr5CktShotoGro.Value, variation-point={short-label=vpIN_VeDMAB_y_StatusByte_AC_RefrigTempSnsr5CktShotoGro_Value, sw-syscond=1}
              IN_VeDMAB_y_StatusByte_AC_RefrigTempSnsrCPerf_Value: accessed-variable=VeDMAB_y_StatusByte_AC_RefrigTempSnsrCPerf.Value, variation-point={short-label=vpIN_VeDMAB_y_StatusByte_AC_RefrigTempSnsrCPerf_Value, sw-syscond=1}
              IN_VeDMAB_y_StatusByte_BattCool_Value: accessed-variable=VeDMAB_y_StatusByte_BattCool.Value, variation-point={short-label=vpIN_VeDMAB_y_StatusByte_BattCool_Value, sw-syscond=1}
              IN_VeDMAB_y_StatusByte_BattCoolLvlLow_Value: accessed-variable=VeDMAB_y_StatusByte_BattCoolLvlLow.Value, variation-point={short-label=vpIN_VeDMAB_y_StatusByte_BattCoolLvlLow_Value, sw-syscond=1}
              IN_VeDMAB_y_StatusByte_BattCoolLvlSnsCkt_Value: accessed-variable=VeDMAB_y_StatusByte_BattCoolLvlSnsCkt.Value, variation-point={short-label=vpIN_VeDMAB_y_StatusByte_BattCoolLvlSnsCkt_Value, sw-syscond=1}
              IN_VeDMAB_y_StatusByte_BattCoolPmpATempSnsrPerf_Value: accessed-variable=VeDMAB_y_StatusByte_BattCoolPmpATempSnsrPerf.Value, variation-point={short-label=vpIN_VeDMAB_y_StatusByte_BattCoolPmpATempSnsrPerf_Value, sw-syscond=1}
              IN_VeDMAB_y_StatusByte_BattCoolPmpHtrBTempSnsrPerf_Value: accessed-variable=VeDMAB_y_StatusByte_BattCoolPmpHtrBTempSnsrPerf.Value, variation-point={short-label=vpIN_VeDMAB_y_StatusByte_BattCoolPmpHtrBTempSnsrPerf_Value, sw-syscond=1}
              IN_VeDMAB_y_StatusByte_BattCoolPmpOveSpd_Value: accessed-variable=VeDMAB_y_StatusByte_BattCoolPmpOveSpd.Value, variation-point={short-label=vpIN_VeDMAB_y_StatusByte_BattCoolPmpOveSpd_Value, sw-syscond=1}
              IN_VeDMAB_y_StatusByte_BattCoolPmpPerf_Value: accessed-variable=VeDMAB_y_StatusByte_BattCoolPmpPerf.Value, variation-point={short-label=vpIN_VeDMAB_y_StatusByte_BattCoolPmpPerf_Value, sw-syscond=1}
              IN_VeDMAB_y_StatusByte_BattHeat_Value: accessed-variable=VeDMAB_y_StatusByte_BattHeat.Value, variation-point={short-label=vpIN_VeDMAB_y_StatusByte_BattHeat_Value, sw-syscond=1}
              IN_VeDMAB_y_StatusByte_CT2_SnsrCktHi_Value: accessed-variable=VeDMAB_y_StatusByte_CT2_SnsrCktHi.Value, variation-point={short-label=vpIN_VeDMAB_y_StatusByte_CT2_SnsrCktHi_Value, sw-syscond=1}
              IN_VeDMAB_y_StatusByte_CT2_SnsrCktLo_Value: accessed-variable=VeDMAB_y_StatusByte_CT2_SnsrCktLo.Value, variation-point={short-label=vpIN_VeDMAB_y_StatusByte_CT2_SnsrCktLo_Value, sw-syscond=1}
              IN_VeDMAB_y_StatusByte_CT2_SnsrPerf_Value: accessed-variable=VeDMAB_y_StatusByte_CT2_SnsrPerf.Value, variation-point={short-label=vpIN_VeDMAB_y_StatusByte_CT2_SnsrPerf_Value, sw-syscond=1}
              IN_VeDMAB_y_StatusByte_CommBusOff_Value: accessed-variable=VeDMAB_y_StatusByte_CommBusOff.Value, variation-point={short-label=vpIN_VeDMAB_y_StatusByte_CommBusOff_Value, sw-syscond=1}
              IN_VeDMAB_y_StatusByte_CommBus_B_Off_Value: accessed-variable=VeDMAB_y_StatusByte_CommBus_B_Off.Value, variation-point={short-label=vpIN_VeDMAB_y_StatusByte_CommBus_B_Off_Value, sw-syscond=1}
              IN_VeDMAB_y_StatusByte_CoolCtrlVlv1Ckt_Value: accessed-variable=VeDMAB_y_StatusByte_CoolCtrlVlv1Ckt.Value, variation-point={short-label=vpIN_VeDMAB_y_StatusByte_CoolCtrlVlv1Ckt_Value, sw-syscond=1}
              IN_VeDMAB_y_StatusByte_CoolCtrlVlv1CktHi_Value: accessed-variable=VeDMAB_y_StatusByte_CoolCtrlVlv1CktHi.Value, variation-point={short-label=vpIN_VeDMAB_y_StatusByte_CoolCtrlVlv1CktHi_Value, sw-syscond=1}
              IN_VeDMAB_y_StatusByte_CoolCtrlVlv1CktLo_Value: accessed-variable=VeDMAB_y_StatusByte_CoolCtrlVlv1CktLo.Value, variation-point={short-label=vpIN_VeDMAB_y_StatusByte_CoolCtrlVlv1CktLo_Value, sw-syscond=1}
              IN_VeDMAB_y_StatusByte_CoolHeaterAPerf_Value: accessed-variable=VeDMAB_y_StatusByte_CoolHeaterAPerf.Value, variation-point={short-label=vpIN_VeDMAB_y_StatusByte_CoolHeaterAPerf_Value, sw-syscond=1}
              IN_VeDMAB_y_StatusByte_CoolOutTempSnsCkt_Value: accessed-variable=VeDMAB_y_StatusByte_CoolOutTempSnsCkt.Value, variation-point={short-label=vpIN_VeDMAB_y_StatusByte_CoolOutTempSnsCkt_Value, sw-syscond=1}
              IN_VeDMAB_y_StatusByte_CoolPmpACtrlCktPerf_Value: accessed-variable=VeDMAB_y_StatusByte_CoolPmpACtrlCktPerf.Value, variation-point={short-label=vpIN_VeDMAB_y_StatusByte_CoolPmpACtrlCktPerf_Value, sw-syscond=1}
              IN_VeDMAB_y_StatusByte_CoolPmpATempSnsrPerf_Value: accessed-variable=VeDMAB_y_StatusByte_CoolPmpATempSnsrPerf.Value, variation-point={short-label=vpIN_VeDMAB_y_StatusByte_CoolPmpATempSnsrPerf_Value, sw-syscond=1}
              IN_VeDMAB_y_StatusByte_CoolantHeaterBPerf_Value: accessed-variable=VeDMAB_y_StatusByte_CoolantHeaterBPerf.Value, variation-point={short-label=vpIN_VeDMAB_y_StatusByte_CoolantHeaterBPerf_Value, sw-syscond=1}
              IN_VeDMAB_y_StatusByte_CoolantVlvA_Ckt_Value: accessed-variable=VeDMAB_y_StatusByte_CoolantVlvA_Ckt.Value, variation-point={short-label=vpIN_VeDMAB_y_StatusByte_CoolantVlvA_Ckt_Value, sw-syscond=1}
              IN_VeDMAB_y_StatusByte_CoolantVlvA_CktHi_Value: accessed-variable=VeDMAB_y_StatusByte_CoolantVlvA_CktHi.Value, variation-point={short-label=vpIN_VeDMAB_y_StatusByte_CoolantVlvA_CktHi_Value, sw-syscond=1}
              IN_VeDMAB_y_StatusByte_CoolantVlvA_CktLo_Value: accessed-variable=VeDMAB_y_StatusByte_CoolantVlvA_CktLo.Value, variation-point={short-label=vpIN_VeDMAB_y_StatusByte_CoolantVlvA_CktLo_Value, sw-syscond=1}
              IN_VeDMAB_y_StatusByte_CoolantVlvA_Perf_Value: accessed-variable=VeDMAB_y_StatusByte_CoolantVlvA_Perf.Value, variation-point={short-label=vpIN_VeDMAB_y_StatusByte_CoolantVlvA_Perf_Value, sw-syscond=1}
              IN_VeDMAB_y_StatusByte_CoolantVlvB_Ckt_Value: accessed-variable=VeDMAB_y_StatusByte_CoolantVlvB_Ckt.Value, variation-point={short-label=vpIN_VeDMAB_y_StatusByte_CoolantVlvB_Ckt_Value, sw-syscond=1}
              IN_VeDMAB_y_StatusByte_CoolantVlvB_CktHi_Value: accessed-variable=VeDMAB_y_StatusByte_CoolantVlvB_CktHi.Value, variation-point={short-label=vpIN_VeDMAB_y_StatusByte_CoolantVlvB_CktHi_Value, sw-syscond=1}
              IN_VeDMAB_y_StatusByte_CoolantVlvB_CktLo_Value: accessed-variable=VeDMAB_y_StatusByte_CoolantVlvB_CktLo.Value, variation-point={short-label=vpIN_VeDMAB_y_StatusByte_CoolantVlvB_CktLo_Value, sw-syscond=1}
              IN_VeDMAB_y_StatusByte_CoolantVlvB_StkClsd_Value: accessed-variable=VeDMAB_y_StatusByte_CoolantVlvB_StkClsd.Value, variation-point={short-label=vpIN_VeDMAB_y_StatusByte_CoolantVlvB_StkClsd_Value, sw-syscond=1}
              IN_VeDMAB_y_StatusByte_EACPerf_Value: accessed-variable=VeDMAB_y_StatusByte_EACPerf.Value, variation-point={short-label=vpIN_VeDMAB_y_StatusByte_EACPerf_Value, sw-syscond=1}
              IN_VeDMAB_y_StatusByte_ECH_TempIn_Value: accessed-variable=VeDMAB_y_StatusByte_ECH_TempIn.Value, variation-point={short-label=vpIN_VeDMAB_y_StatusByte_ECH_TempIn_Value, sw-syscond=1}
              IN_VeDMAB_y_StatusByte_ECH_TempOut_Value: accessed-variable=VeDMAB_y_StatusByte_ECH_TempOut.Value, variation-point={short-label=vpIN_VeDMAB_y_StatusByte_ECH_TempOut_Value, sw-syscond=1}
              IN_VeDMAB_y_StatusByte_HB_CT_SnsrPerf_Value: accessed-variable=VeDMAB_y_StatusByte_HB_CT_SnsrPerf.Value, variation-point={short-label=vpIN_VeDMAB_y_StatusByte_HB_CT_SnsrPerf_Value, sw-syscond=1}
              IN_VeDMAB_y_StatusByte_HeatingElmntPerf_Value: accessed-variable=VeDMAB_y_StatusByte_HeatingElmntPerf.Value, variation-point={short-label=vpIN_VeDMAB_y_StatusByte_HeatingElmntPerf_Value, sw-syscond=1}
              IN_VeDMAB_y_StatusByte_LIN{1..3}_BusOff_Value: accessed-variable=VeDMAB_y_StatusByte_LIN{1..3}_BusOff.Value, variation-point={short-label=vpIN_VeDMAB_y_StatusByte_LIN{1..3}_BusOff_Value, sw-syscond=1}
              IN_VeDMAB_y_StatusByte_LosCommBECM_A_Value: accessed-variable=VeDMAB_y_StatusByte_LosCommBECM_A.Value, variation-point={short-label=vpIN_VeDMAB_y_StatusByte_LosCommBECM_A_Value, sw-syscond=1}
              IN_VeDMAB_y_StatusByte_LosCommBECM_A_CANC11_Value: accessed-variable=VeDMAB_y_StatusByte_LosCommBECM_A_CANC11.Value, variation-point={short-label=vpIN_VeDMAB_y_StatusByte_LosCommBECM_A_CANC11_Value, sw-syscond=1}
              IN_VeDMAB_y_StatusByte_LostCommACRefrigExpVlvActA_Value: accessed-variable=VeDMAB_y_StatusByte_LostCommACRefrigExpVlvActA.Value, variation-point={short-label=vpIN_VeDMAB_y_StatusByte_LostCommACRefrigExpVlvActA_Value, sw-syscond=1}
              IN_VeDMAB_y_StatusByte_LostCommACRefrigExpVlvActC_Value: accessed-variable=VeDMAB_y_StatusByte_LostCommACRefrigExpVlvActC.Value, variation-point={short-label=vpIN_VeDMAB_y_StatusByte_LostCommACRefrigExpVlvActC_Value, sw-syscond=1}
              IN_VeDMAB_y_StatusByte_LostCommACRefrigExpVlvActD_Value: accessed-variable=VeDMAB_y_StatusByte_LostCommACRefrigExpVlvActD.Value, variation-point={short-label=vpIN_VeDMAB_y_StatusByte_LostCommACRefrigExpVlvActD_Value, sw-syscond=1}
              IN_VeDMAB_y_StatusByte_LostCommCoolHtrA_Value: accessed-variable=VeDMAB_y_StatusByte_LostCommCoolHtrA.Value, variation-point={short-label=vpIN_VeDMAB_y_StatusByte_LostCommCoolHtrA_Value, sw-syscond=1}
              IN_VeDMAB_y_StatusByte_LostCommCoolPmpA_Value: accessed-variable=VeDMAB_y_StatusByte_LostCommCoolPmpA.Value, variation-point={short-label=vpIN_VeDMAB_y_StatusByte_LostCommCoolPmpA_Value, sw-syscond=1}
              IN_VeDMAB_y_StatusByte_LostCommEAC_Value: accessed-variable=VeDMAB_y_StatusByte_LostCommEAC.Value, variation-point={short-label=vpIN_VeDMAB_y_StatusByte_LostCommEAC_Value, sw-syscond=1}
              IN_VeDMAB_y_StatusByte_LostCommHB_CoolPmp_Value: accessed-variable=VeDMAB_y_StatusByte_LostCommHB_CoolPmp.Value, variation-point={short-label=vpIN_VeDMAB_y_StatusByte_LostCommHB_CoolPmp_Value, sw-syscond=1}
              IN_VeDMAB_y_StatusByte_LostCommHighVolCabinAirHtr_Value: accessed-variable=VeDMAB_y_StatusByte_LostCommHighVolCabinAirHtr.Value, variation-point={short-label=vpIN_VeDMAB_y_StatusByte_LostCommHighVolCabinAirHtr_Value, sw-syscond=1}
              IN_VeDMAB_y_StatusByte_ThrmlRlyCtrlCkt_Value: accessed-variable=VeDMAB_y_StatusByte_ThrmlRlyCtrlCkt.Value, variation-point={short-label=vpIN_VeDMAB_y_StatusByte_ThrmlRlyCtrlCkt_Value, sw-syscond=1}
              IN_VeFSCR_b_RadFan_FltDtct_Value: accessed-variable=VeFSCR_b_RadFan_FltDtct.Value, variation-point={short-label=vpIN_VeFSCR_b_RadFan_FltDtct_Value, sw-syscond=1}
              IN_VeHPMR_e_HybSysSt_Value: accessed-variable=VeHPMR_e_HybSysSt.Value, variation-point={short-label=vpIN_VeHPMR_e_HybSysSt_Value, sw-syscond=1}
              IN_VeHSWR_b_HoodOpen_Value: accessed-variable=VeHSWR_b_HoodOpen.Value, variation-point={short-label=vpIN_VeHSWR_b_HoodOpen_Value, sw-syscond=1}
              IN_VeHTIR_T_HVC_Htr4ClntOut_Temp_Value: accessed-variable=VeHTIR_T_HVC_Htr4ClntOut_Temp.Value, variation-point={short-label=vpIN_VeHTIR_T_HVC_Htr4ClntOut_Temp_Value, sw-syscond=1}
              IN_VeHTIR_e_HV_ElecClntHtr3_Sts_Value: accessed-variable=VeHTIR_e_HV_ElecClntHtr3_Sts.Value, variation-point={short-label=vpIN_VeHTIR_e_HV_ElecClntHtr3_Sts_Value, sw-syscond=1}
              IN_VeHTIR_e_HV_ElecClntHtr4_Sts_Value: accessed-variable=VeHTIR_e_HV_ElecClntHtr4_Sts.Value, variation-point={short-label=vpIN_VeHTIR_e_HV_ElecClntHtr4_Sts_Value, sw-syscond=1}
              IN_VeIDCR_T_APMTemp1_Value: accessed-variable=VeIDCR_T_APMTemp1.Value, variation-point={short-label=vpIN_VeIDCR_T_APMTemp1_Value, sw-syscond=1}
              IN_VeIDCR_T_APMTemp2_Value: accessed-variable=VeIDCR_T_APMTemp2.Value, variation-point={short-label=vpIN_VeIDCR_T_APMTemp2_Value, sw-syscond=1}
              IN_VeOBCR_e_ChargingLevel_Value: accessed-variable=VeOBCR_e_ChargingLevel.Value, variation-point={short-label=vpIN_VeOBCR_e_ChargingLevel_Value, sw-syscond=1}
              IN_VeOBCR_e_ChargingSystemSts_Value: accessed-variable=VeOBCR_e_ChargingSystemSts.Value, variation-point={short-label=vpIN_VeOBCR_e_ChargingSystemSts_Value, sw-syscond=1}
              IN_VePDTR_e_EngOrBattPwrDschg_State_Value: accessed-variable=VePDTR_e_EngOrBattPwrDschg_State.Value, variation-point={short-label=vpIN_VePDTR_e_EngOrBattPwrDschg_State_Value, sw-syscond=1}
              IN_VePMIR_T_LTActvPumpTemp_Value: accessed-variable=VePMIR_T_LTActvPumpTemp.Value, variation-point={short-label=vpIN_VePMIR_T_LTActvPumpTemp_Value, sw-syscond=1}
              IN_VePMIR_b_HTAuxPumpDryRun_FA_Value: accessed-variable=VePMIR_b_HTAuxPumpDryRun_FA.Value, variation-point={short-label=vpIN_VePMIR_b_HTAuxPumpDryRun_FA_Value, sw-syscond=1}
              IN_VePMIR_b_LTActvPumpDryRun_FA_Value: accessed-variable=VePMIR_b_LTActvPumpDryRun_FA.Value, variation-point={short-label=vpIN_VePMIR_b_LTActvPumpDryRun_FA_Value, sw-syscond=1}
              IN_VePMIR_e_HTAuxPumpDryRun_Value: accessed-variable=VePMIR_e_HTAuxPumpDryRun.Value, variation-point={short-label=vpIN_VePMIR_e_HTAuxPumpDryRun_Value, sw-syscond=1}
              IN_VePMIR_e_LTActvPumpDryRun_Value: accessed-variable=VePMIR_e_LTActvPumpDryRun.Value, variation-point={short-label=vpIN_VePMIR_e_LTActvPumpDryRun_Value, sw-syscond=1}
              IN_VePMTR_b_ThrmlSystRly_EnblCmnd_Value: accessed-variable=VePMTR_b_ThrmlSystRly_EnblCmnd.Value, variation-point={short-label=vpIN_VePMTR_b_ThrmlSystRly_EnblCmnd_Value, sw-syscond=1}
              IN_VePWDR_e_HVOverVoltFailure_Value: accessed-variable=VePWDR_e_HVOverVoltFailure.Value, variation-point={short-label=vpIN_VePWDR_e_HVOverVoltFailure_Value, sw-syscond=1}
              IN_VeRCVR_e_CPV_Valve_Stuck_State_Value: accessed-variable=VeRCVR_e_CPV_Valve_Stuck_State.Value, variation-point={short-label=vpIN_VeRCVR_e_CPV_Valve_Stuck_State_Value, sw-syscond=1}
              IN_VeRCVR_e_HTL_Valve_Stuck_State_Value: accessed-variable=VeRCVR_e_HTL_Valve_Stuck_State.Value, variation-point={short-label=vpIN_VeRCVR_e_HTL_Valve_Stuck_State_Value, sw-syscond=1}
              IN_VeRCVR_e_LTR_Valve_Stuck_State_Value: accessed-variable=VeRCVR_e_LTR_Valve_Stuck_State.Value, variation-point={short-label=vpIN_VeRCVR_e_LTR_Valve_Stuck_State_Value, sw-syscond=1}
              IN_VeSSDR_e_KeySts_Value: accessed-variable=VeSSDR_e_KeySts.Value, variation-point={short-label=vpIN_VeSSDR_e_KeySts_Value, sw-syscond=1}
              IN_VeTAIR_p_HghRfrgtPres_Value: accessed-variable=VeTAIR_p_HghRfrgtPres.Value, variation-point={short-label=vpIN_VeTAIR_p_HghRfrgtPres_Value, sw-syscond=1}
              IN_VeTHMR_T_AHPInletTempArb_Value: accessed-variable=VeTHMR_T_AHPInletTempArb.Value, variation-point={short-label=vpIN_VeTHMR_T_AHPInletTempArb_Value, sw-syscond=1}
              IN_VeTHMR_T_LTCLTgt_BattActvPsvHeating_Value: accessed-variable=VeTHMR_T_LTCLTgt_BattActvPsvHeating.Value, variation-point={short-label=vpIN_VeTHMR_T_LTCLTgt_BattActvPsvHeating_Value, sw-syscond=1}
              IN_VeTHMR_T_MaxBattAllow_Value: accessed-variable=VeTHMR_T_MaxBattAllow.Value, variation-point={short-label=vpIN_VeTHMR_T_MaxBattAllow_Value, sw-syscond=1}
              IN_VeTHMR_T_MaxBattAllowPsv_Value: accessed-variable=VeTHMR_T_MaxBattAllowPsv.Value, variation-point={short-label=vpIN_VeTHMR_T_MaxBattAllowPsv_Value, sw-syscond=1}
              IN_VeTHMR_T_MinBattAllow_Value: accessed-variable=VeTHMR_T_MinBattAllow.Value, variation-point={short-label=vpIN_VeTHMR_T_MinBattAllow_Value, sw-syscond=1}
              IN_VeTHMR_T_MinBattAllowPsv_Value: accessed-variable=VeTHMR_T_MinBattAllowPsv.Value, variation-point={short-label=vpIN_VeTHMR_T_MinBattAllowPsv_Value, sw-syscond=1}
              IN_VeTHMR_b_HVBR_UsgEnb_Value: accessed-variable=VeTHMR_b_HVBR_UsgEnb.Value, variation-point={short-label=vpIN_VeTHMR_b_HVBR_UsgEnb_Value, sw-syscond=1}
              IN_VeTHMR_b_HV_BatRdyLocal_True_Value: accessed-variable=VeTHMR_b_HV_BatRdyLocal_True.Value, variation-point={short-label=vpIN_VeTHMR_b_HV_BatRdyLocal_True_Value, sw-syscond=1}
              IN_VeTHMR_b_LTAP_ExpctdOff_Value: accessed-variable=VeTHMR_b_LTAP_ExpctdOff.Value, variation-point={short-label=vpIN_VeTHMR_b_LTAP_ExpctdOff_Value, sw-syscond=1}
              IN_VeTHMR_b_RS_N_Or_NrmlPerWp_Value: accessed-variable=VeTHMR_b_RS_N_Or_NrmlPerWp.Value, variation-point={short-label=vpIN_VeTHMR_b_RS_N_Or_NrmlPerWp_Value, sw-syscond=1}
              IN_VeTHMR_e_BatThrmlSt_Value: accessed-variable=VeTHMR_e_BatThrmlSt.Value, variation-point={short-label=vpIN_VeTHMR_e_BatThrmlSt_Value, sw-syscond=1}
              IN_VeTHMR_e_CabHeatThermalState_Value: accessed-variable=VeTHMR_e_CabHeatThermalState.Value, variation-point={short-label=vpIN_VeTHMR_e_CabHeatThermalState_Value, sw-syscond=1}
              IN_VeTHMR_e_HTCL_Heat_Distrib_Value: accessed-variable=VeTHMR_e_HTCL_Heat_Distrib.Value, variation-point={short-label=vpIN_VeTHMR_e_HTCL_Heat_Distrib_Value, sw-syscond=1}
              IN_VeTHMR_e_VehThermSt_Value: accessed-variable=VeTHMR_e_VehThermSt.Value, variation-point={short-label=vpIN_VeTHMR_e_VehThermSt_Value, sw-syscond=1}
              IN_VeTMIR_T_PsvPmpClnt_TmpIn_Value: accessed-variable=VeTMIR_T_PsvPmpClnt_TmpIn.Value, variation-point={short-label=vpIN_VeTMIR_T_PsvPmpClnt_TmpIn_Value, sw-syscond=1}
              IN_VeTMIR_b_PsvPmpClnt_TmpIn_FA_Value: accessed-variable=VeTMIR_b_PsvPmpClnt_TmpIn_FA.Value, variation-point={short-label=vpIN_VeTMIR_b_PsvPmpClnt_TmpIn_FA_Value, sw-syscond=1}
              IN_VeTPCR_dT_PerWpCond_BatTmpErr_Value: accessed-variable=VeTPCR_dT_PerWpCond_BatTmpErr.Value, variation-point={short-label=vpIN_VeTPCR_dT_PerWpCond_BatTmpErr_Value, sw-syscond=1}
              IN_VeTPCR_e_PerWup_BattEngCond_State_Value: accessed-variable=VeTPCR_e_PerWup_BattEngCond_State.Value, variation-point={short-label=vpIN_VeTPCR_e_PerWup_BattEngCond_State_Value, sw-syscond=1}
              IN_VeTRIR_T_HV_BatClntTmp2_In_Value: accessed-variable=VeTRIR_T_HV_BatClntTmp2_In.Value, variation-point={short-label=vpIN_VeTRIR_T_HV_BatClntTmp2_In_Value, sw-syscond=1}
              IN_VeTRIR_T_HV_BatClntTmpOut_Value: accessed-variable=VeTRIR_T_HV_BatClntTmpOut.Value, variation-point={short-label=vpIN_VeTRIR_T_HV_BatClntTmpOut_Value, sw-syscond=1}
              IN_VeTRIR_T_HV_BatClntTmpOut2_Value: accessed-variable=VeTRIR_T_HV_BatClntTmpOut2.Value, variation-point={short-label=vpIN_VeTRIR_T_HV_BatClntTmpOut2_Value, sw-syscond=1}
              IN_VeVLDR_b_EEXV_PerfDiag_FltDtct_Value: accessed-variable=VeVLDR_b_EEXV_PerfDiag_FltDtct.Value, variation-point={short-label=vpIN_VeVLDR_b_EEXV_PerfDiag_FltDtct_Value, sw-syscond=1}
              IN_VeVLDR_b_EEXV_PressSens_FltDtct_Value: accessed-variable=VeVLDR_b_EEXV_PressSens_FltDtct.Value, variation-point={short-label=vpIN_VeVLDR_b_EEXV_PressSens_FltDtct_Value, sw-syscond=1}
              IN_VeVLDR_b_EXV_PerfDiag_FltDtct_Value: accessed-variable=VeVLDR_b_EXV_PerfDiag_FltDtct.Value, variation-point={short-label=vpIN_VeVLDR_b_EXV_PerfDiag_FltDtct_Value, sw-syscond=1}
              IN_VeVLDR_b_EXV_PressElctrFlt_FltDtct_Value: accessed-variable=VeVLDR_b_EXV_PressElctrFlt_FltDtct.Value, variation-point={short-label=vpIN_VeVLDR_b_EXV_PressElctrFlt_FltDtct_Value, sw-syscond=1}
              IN_VeVLDR_b_EXV_PressSens_FltDtct_Value: accessed-variable=VeVLDR_b_EXV_PressSens_FltDtct.Value, variation-point={short-label=vpIN_VeVLDR_b_EXV_PressSens_FltDtct_Value, sw-syscond=1}
              IN_VeVLDR_b_EXV_TempElctrFlt_FltDtct_Value: accessed-variable=VeVLDR_b_EXV_TempElctrFlt_FltDtct.Value, variation-point={short-label=vpIN_VeVLDR_b_EXV_TempElctrFlt_FltDtct_Value, sw-syscond=1}
              IN_VeVLDR_b_EXV_TempSens_FltDtct_Value: accessed-variable=VeVLDR_b_EXV_TempSens_FltDtct.Value, variation-point={short-label=vpIN_VeVLDR_b_EXV_TempSens_FltDtct_Value, sw-syscond=1}
              IN_VeVLDR_b_OEXV_PerfDiag_FltDtct_Value: accessed-variable=VeVLDR_b_OEXV_PerfDiag_FltDtct.Value, variation-point={short-label=vpIN_VeVLDR_b_OEXV_PerfDiag_FltDtct_Value, sw-syscond=1}
              IN_VeVLDR_b_OEXV_PressElctrFlt_FltDtct_Value: accessed-variable=VeVLDR_b_OEXV_PressElctrFlt_FltDtct.Value, variation-point={short-label=vpIN_VeVLDR_b_OEXV_PressElctrFlt_FltDtct_Value, sw-syscond=1}
              IN_VeVLDR_b_OEXV_PressSens_FltDtct_Value: accessed-variable=VeVLDR_b_OEXV_PressSens_FltDtct.Value, variation-point={short-label=vpIN_VeVLDR_b_OEXV_PressSens_FltDtct_Value, sw-syscond=1}
          data-send-points:
            36 x access:
              OUT_VeBTRR_b_BattHeatReq_Value: accessed-variable=VeBTRR_b_BattHeatReq.Value, variation-point={short-label=vpOUT_VeBTRR_b_BattHeatReq_Value, sw-syscond=1}
              OUT_VeBTRR_b_isCharging_Value: accessed-variable=VeBTRR_b_isCharging.Value, variation-point={short-label=vpOUT_VeBTRR_b_isCharging_Value, sw-syscond=1}
              OUT_VeBTRR_b_BattCondPlugin_Rq_Value: accessed-variable=VeBTRR_b_BattCondPlugin_Rq.Value, variation-point={short-label=vpOUT_VeBTRR_b_BattCondPlugin_Rq_Value, sw-syscond=1}
              OUT_VeBTRR_b_PlugdIn_Or_Chrg_Value: accessed-variable=VeBTRR_b_PlugdIn_Or_Chrg.Value, variation-point={short-label=vpOUT_VeBTRR_b_PlugdIn_Or_Chrg_Value, sw-syscond=1}
              OUT_VeBTRR_b_OoR_Recoverable_Value: accessed-variable=VeBTRR_b_OoR_Recoverable.Value, variation-point={short-label=vpOUT_VeBTRR_b_OoR_Recoverable_Value, sw-syscond=1}
              OUT_VeBTRR_dT_CellOverTempPsv_Value: accessed-variable=VeBTRR_dT_CellOverTempPsv.Value, variation-point={short-label=vpOUT_VeBTRR_dT_CellOverTempPsv_Value, sw-syscond=1}
              OUT_VeBTRR_b_BattCellBalancing_Value: accessed-variable=VeBTRR_b_BattCellBalancing.Value, variation-point={short-label=vpOUT_VeBTRR_b_BattCellBalancing_Value, sw-syscond=1}
              OUT_VeBTRR_e_HV_BatTmpRng_Value: accessed-variable=VeBTRR_e_HV_BatTmpRng.Value, variation-point={short-label=vpOUT_VeBTRR_e_HV_BatTmpRng_Value, sw-syscond=1}
              OUT_VeBTRR_b_Batt_CritOrMarg_Value: accessed-variable=VeBTRR_b_Batt_CritOrMarg.Value, variation-point={short-label=vpOUT_VeBTRR_b_Batt_CritOrMarg_Value, sw-syscond=1}
              OUT_VeBTRR_e_BatCondPriority_Value: accessed-variable=VeBTRR_e_BatCondPriority.Value, variation-point={short-label=vpOUT_VeBTRR_e_BatCondPriority_Value, sw-syscond=1}
              OUT_VeBTRR_b_BattTempNot_Optml_Value: accessed-variable=VeBTRR_b_BattTempNot_Optml.Value, variation-point={short-label=vpOUT_VeBTRR_b_BattTempNot_Optml_Value, sw-syscond=1}
              OUT_VeBTRR_b_VhclPlgdIn_Value: accessed-variable=VeBTRR_b_VhclPlgdIn.Value, variation-point={short-label=vpOUT_VeBTRR_b_VhclPlgdIn_Value, sw-syscond=1}
              OUT_VeBTRR_P_BatHeatPwr_NeedLimtd_Value: accessed-variable=VeBTRR_P_BatHeatPwr_NeedLimtd.Value, variation-point={short-label=vpOUT_VeBTRR_P_BatHeatPwr_NeedLimtd_Value, sw-syscond=1}
              OUT_VeBTRR_P_BattCoolPwrNeedLim_Value: accessed-variable=VeBTRR_P_BattCoolPwrNeedLim.Value, variation-point={short-label=vpOUT_VeBTRR_P_BattCoolPwrNeedLim_Value, sw-syscond=1}
              OUT_VeBTRR_b_ThrmlBatCoolingFlt_Value: accessed-variable=VeBTRR_b_ThrmlBatCoolingFlt.Value, variation-point={short-label=vpOUT_VeBTRR_b_ThrmlBatCoolingFlt_Value, sw-syscond=1}
              OUT_VeBTRR_T_BTISBTIS2_Max_Value: accessed-variable=VeBTRR_T_BTISBTIS2_Max.Value, variation-point={short-label=vpOUT_VeBTRR_T_BTISBTIS2_Max_Value, sw-syscond=1}
              OUT_VeBTRR_T_BattDisplayTemp_Value: accessed-variable=VeBTRR_T_BattDisplayTemp.Value, variation-point={short-label=vpOUT_VeBTRR_T_BattDisplayTemp_Value, sw-syscond=1}
              OUT_VeBTRR_b_BattCondFlt_Value: accessed-variable=VeBTRR_b_BattCondFlt.Value, variation-point={short-label=vpOUT_VeBTRR_b_BattCondFlt_Value, sw-syscond=1}
              OUT_VeBTRR_b_HVBattPriority_Value: accessed-variable=VeBTRR_b_HVBattPriority.Value, variation-point={short-label=vpOUT_VeBTRR_b_HVBattPriority_Value, sw-syscond=1}
              OUT_VeBTRR_b_BattCoolFlts_Value: accessed-variable=VeBTRR_b_BattCoolFlts.Value, variation-point={short-label=vpOUT_VeBTRR_b_BattCoolFlts_Value, sw-syscond=1}
              OUT_VeBTRR_b_KeyRun_OV_BattCrit_Value: accessed-variable=VeBTRR_b_KeyRun_OV_BattCrit.Value, variation-point={short-label=vpOUT_VeBTRR_b_KeyRun_OV_BattCrit_Value, sw-syscond=1}
              OUT_VeBTRR_b_Psv_BattHeatReq_Value: accessed-variable=VeBTRR_b_Psv_BattHeatReq.Value, variation-point={short-label=vpOUT_VeBTRR_b_Psv_BattHeatReq_Value, sw-syscond=1}
              OUT_VeBTRR_T_BattTmp_MaxDerateZone_Value: accessed-variable=VeBTRR_T_BattTmp_MaxDerateZone.Value, variation-point={short-label=vpOUT_VeBTRR_T_BattTmp_MaxDerateZone_Value, sw-syscond=1}
              OUT_VeBTRR_T_BattTmp_MinDerateZone_Value: accessed-variable=VeBTRR_T_BattTmp_MinDerateZone.Value, variation-point={short-label=vpOUT_VeBTRR_T_BattTmp_MinDerateZone_Value, sw-syscond=1}
              OUT_VeBTRR_dT_CellUnderTemp_Value: accessed-variable=VeBTRR_dT_CellUnderTemp.Value, variation-point={short-label=vpOUT_VeBTRR_dT_CellUnderTemp_Value, sw-syscond=1}
              OUT_VeBTRR_T_BattTmp_MinCmfrtZone_Value: accessed-variable=VeBTRR_T_BattTmp_MinCmfrtZone.Value, variation-point={short-label=vpOUT_VeBTRR_T_BattTmp_MinCmfrtZone_Value, sw-syscond=1}
              OUT_VeBTRR_T_BattTmp_MaxCmfrtZone_Value: accessed-variable=VeBTRR_T_BattTmp_MaxCmfrtZone.Value, variation-point={short-label=vpOUT_VeBTRR_T_BattTmp_MaxCmfrtZone_Value, sw-syscond=1}
              OUT_VeBTRR_b_BattCoolReq_Value: accessed-variable=VeBTRR_b_BattCoolReq.Value, variation-point={short-label=vpOUT_VeBTRR_b_BattCoolReq_Value, sw-syscond=1}
              OUT_VeBTRR_b_Batt_PsvCoolReq_Value: accessed-variable=VeBTRR_b_Batt_PsvCoolReq.Value, variation-point={short-label=vpOUT_VeBTRR_b_Batt_PsvCoolReq_Value, sw-syscond=1}
              OUT_VeBTRR_b_BattCoolReq_CPV_RA_Value: accessed-variable=VeBTRR_b_BattCoolReq_CPV_RA.Value, variation-point={short-label=vpOUT_VeBTRR_b_BattCoolReq_CPV_RA_Value, sw-syscond=1}
              OUT_VeBTRR_b_BattHeatingFlts_Value: accessed-variable=VeBTRR_b_BattHeatingFlts.Value, variation-point={short-label=vpOUT_VeBTRR_b_BattHeatingFlts_Value, sw-syscond=1}
              OUT_VeBTRR_dT_CellOverTemp_Value: accessed-variable=VeBTRR_dT_CellOverTemp.Value, variation-point={short-label=vpOUT_VeBTRR_dT_CellOverTemp_Value, sw-syscond=1}
              OUT_VeBTRR_dV_LT_ActPmpFlw_Value: accessed-variable=VeBTRR_dV_LT_ActPmpFlw.Value, variation-point={short-label=vpOUT_VeBTRR_dV_LT_ActPmpFlw_Value, sw-syscond=1}
              OUT_VeBTRR_b_PerWup_BatToCond_Value: accessed-variable=VeBTRR_b_PerWup_BatToCond.Value, variation-point={short-label=vpOUT_VeBTRR_b_PerWup_BatToCond_Value, sw-syscond=1}
              OUT_VeBTRR_b_HV_BatTempCrit_Cond_Value: accessed-variable=VeBTRR_b_HV_BatTempCrit_Cond.Value, variation-point={short-label=vpOUT_VeBTRR_b_HV_BatTempCrit_Cond_Value, sw-syscond=1}
              OUT_VeBTRR_e_HV_BatTempCrit_CondState_New_Value: accessed-variable=VeBTRR_e_HV_BatTempCrit_CondState_New.Value, variation-point={short-label=vpOUT_VeBTRR_e_HV_BatTempCrit_CondState_New_Value, sw-syscond=1}
          read-local-variables:
            13 x access:
              RV_BatTmpCold_RgHgh_D_write_IRV: accessed-variable=BatTmpCold_RgHgh_D_write_IRV, variation-point={short-label=vpRV_BatTmpCold_RgHgh_D_write_IRV, sw-syscond=1}
              RV_BatTmpCold_RgLw_D_write_IRV: accessed-variable=BatTmpCold_RgLw_D_write_IRV, variation-point={short-label=vpRV_BatTmpCold_RgLw_D_write_IRV, sw-syscond=1}
              RV_BatTmpHys_ColdRgHgh_D_write_IRV: accessed-variable=BatTmpHys_ColdRgHgh_D_write_IRV, variation-point={short-label=vpRV_BatTmpHys_ColdRgHgh_D_write_IRV, sw-syscond=1}
              RV_BatTmpHys_ColdRgLw_D_write_IRV: accessed-variable=BatTmpHys_ColdRgLw_D_write_IRV, variation-point={short-label=vpRV_BatTmpHys_ColdRgLw_D_write_IRV, sw-syscond=1}
              RV_CellTempDelta_Raw_write_IRV: accessed-variable=CellTempDelta_Raw_write_IRV, variation-point={short-label=vpRV_CellTempDelta_Raw_write_IRV, sw-syscond=1}
              RV_CellTempDelta_write_IRV: accessed-variable=CellTempDelta_write_IRV, variation-point={short-label=vpRV_CellTempDelta_write_IRV, sw-syscond=1}
              RV_CellTempMaxFA_write_IRV: accessed-variable=CellTempMaxFA_write_IRV, variation-point={short-label=vpRV_CellTempMaxFA_write_IRV, sw-syscond=1}
              RV_CellTempMaxUsed_write_IRV: accessed-variable=CellTempMaxUsed_write_IRV, variation-point={short-label=vpRV_CellTempMaxUsed_write_IRV, sw-syscond=1}
              RV_CellTempMinFA_write_IRV: accessed-variable=CellTempMinFA_write_IRV, variation-point={short-label=vpRV_CellTempMinFA_write_IRV, sw-syscond=1}
              RV_CellTempMinUsed_write_IRV: accessed-variable=CellTempMinUsed_write_IRV, variation-point={short-label=vpRV_CellTempMinUsed_write_IRV, sw-syscond=1}
              RV_HVBR_Ovrd_Req_write_IRV: accessed-variable=HVBR_Ovrd_Req_write_IRV, variation-point={short-label=vpRV_HVBR_Ovrd_Req_write_IRV, sw-syscond=1}
              RV_HV_BatClntTmp_In_AftDial_write_IRV: accessed-variable=HV_BatClntTmp_In_AftDial_write_IRV, variation-point={short-label=vpRV_HV_BatClntTmp_In_AftDial_write_IRV, sw-syscond=1}
              RV_PropSysActv_BTRR_AftDial_write_IRV: accessed-variable=PropSysActv_BTRR_AftDial_write_IRV, variation-point={short-label=vpRV_PropSysActv_BTRR_AftDial_write_IRV, sw-syscond=1}
      4 x variation point proxy, all with category=CONDITION:
        Variant_BTRR_1: condition-access=1
        Variant_BTRR_2: condition-access=1
        Variant_BTRR_3: condition-access=0
        Variant_BTRR_5: condition-access=0
